VERSION ""

NS_ :

BS_:

BU_: TPMS
VAL_TABLE_ FMI 31 "Not available" 19 "Received network data in error" 18 "Below normal (moderately severe)" 17 "Below normal (least severe)" 16 "Above normal (moderately severe)" 15 "Above normal (least severe)" 14 "Special intstructions" 13 "Out of calibration" 12 "Bad intelligent device" 11 "Root cause not known" 10 "Abnormal rate of change" 9 "Abnormal update rate" 8 "Abnormal frequency" 7 "Mechanical system not responding" 6 "Current above normal" 5 "Current below normal" 4 "Voltage below normal" 3 "Voltage above normal" 2 "Data erratic" 1 "Below normal (most severe)" 0 "Above normal (most severe)" ;

BO_ 3221225472 VECTOR__INDEPENDENT_SIG_MSG: 0 Vector__XXX
 SG_ ParameterGroupNumber : 0|24@1- (1,0) [0|16777215] "" Vector__XXX
 SG_ TireTemp : 0|16@1+ (0.03125,-273) [-273|1734.96875] "deg C" Vector__XXX
 SG_ TirePressThresholdDetection : 0|3@1+ (1,0) [0|7] "" Vector__XXX
 SG_ TirePress : 0|8@1+ (4,0) [0|1000] "kPa" Vector__XXX
 SG_ TrailerWeight : 0|16@1+ (2,0) [0|128510] "kg" Vector__XXX
 SG_ TireAirLeakageRate : 0|16@1+ (0.1,0) [0|6425.5] "Pa/s" Vector__XXX
 SG_ ReferenceTirePressSetting : 0|8@1+ (1,0) [0|2000] "kPa" Vector__XXX
 SG_ ReferenceTirePress : 0|8@1+ (1,0) [0|2000] "kPa" Vector__XXX
 SG_ CTIWheelEndElectricalFault : 0|2@1+ (1,0) [0|3] "" Vector__XXX
 SG_ CTITireStatus : 0|2@1+ (1,0) [0|3] "" Vector__XXX
 SG_ CTIWheelSensorStatus : 0|2@1+ (1,0) [0|3] "" Vector__XXX
 SG_ EngTurningGearEngaged : 0|2@1+ (1,0) [0|3] "" Vector__XXX

BO_ 2684354558 CAPL_MSG: 1785 Vector__XXX

BO_ 2566838526 CA: 9 Vector__XXX
 SG_ AddressAssignment : 64|8@1+ (1,0) [0|255] "" Vector__XXX
 SG_ ArbitraryAddressCapable : 63|1@1+ (1,0) [0|1] "" Vector__XXX
 SG_ IndustryGroup M : 60|3@1+ (1,0) [0|7] "" Vector__XXX
 SG_ VehicleSystemInstance : 56|4@1+ (1,0) [0|15] "" Vector__XXX
 SG_ Function : 40|8@1+ (1,0) [0|255] "" Vector__XXX
 SG_ VehicleSystem m0 : 49|7@1+ (1,0) [0|127] "" Vector__XXX
 SG_ FunctionInstance : 35|5@1+ (1,0) [0|31] "" Vector__XXX
 SG_ ECUInstance : 32|3@1+ (1,0) [0|7] "" Vector__XXX
 SG_ ManufacturerCode : 21|11@1+ (1,0) [0|2047] "" Vector__XXX
 SG_ IdentityNumber : 0|21@1+ (1,0) [0|2097152] "" Vector__XXX
 SG_ VehicleSystem5 m5 : 49|7@1+ (1,0) [0|127] "" Vector__XXX
 SG_ VehicleSystem4 m4 : 49|7@1+ (1,0) [0|127] "" Vector__XXX
 SG_ VehicleSystem3 m3 : 49|7@1+ (1,0) [0|127] "" Vector__XXX
 SG_ VehicleSystem2 m2 : 49|7@1+ (1,0) [0|127] "" Vector__XXX
 SG_ VehicleSystem1 m1 : 49|7@1+ (1,0) [0|127] "" Vector__XXX

BO_ 2565537534 RQST: 8 Vector__XXX
 SG_ ParameterGroupNumber : 0|24@1+ (1,0) [0|16777215] "" Vector__XXX

BO_ 2632711934 TPDT: 8 Vector__XXX
 SG_ SequenceNumber : 0|8@1+ (1,0) [0|255] "" Vector__XXX

BO_ 2632777470 TPCM: 8 Vector__XXX
 SG_ TotalNumberOfPacketsEoMA m19 : 24|8@1+ (1,0) [0|255] "" Vector__XXX
 SG_ TotalMessageSizeEoMA m19 : 8|16@1+ (1,0) [0|64255] "counts" Vector__XXX
 SG_ TotalMessageSizeBAM m32 : 8|16@1+ (1,0) [0|64255] "counts" Vector__XXX
 SG_ TotalNumberOfPacketsBAM m32 : 24|8@1+ (1,0) [0|255] "" Vector__XXX
 SG_ ConnectionAbortReason m255 : 8|8@1+ (1,0) [0|255] "" Vector__XXX
 SG_ NextPacketNumberToBeSent m17 : 16|8@1+ (1,0) [0|255] "" Vector__XXX
 SG_ NumberOfPacketsThatCanBeSent m17 : 8|8@1+ (1,0) [0|255] "" Vector__XXX
 SG_ PGNumber : 40|24@1+ (1,0) [0|16777200] "" Vector__XXX
 SG_ MaximumNumberOfPackets m16 : 32|8@1+ (1,0) [0|255] "" Vector__XXX
 SG_ TotalNumberOfPackets m16 : 24|8@1+ (1,0) [0|255] "" Vector__XXX
 SG_ TotalMessageSize m16 : 8|16@1+ (1,0) [0|64255] "counts" Vector__XXX
 SG_ ControlByte M : 0|8@1+ (1,0) [0|255] "" Vector__XXX

BO_ 2561605374 TPRS: 8 Vector__XXX
 SG_ TireLocation M : 0|8@1+ (1,0) [0|255] "" Vector__XXX
 SG_ ReferenceTirePressSetting_00 m0 : 8|8@1+ (8,0) [0|2000] "kPa" Vector__XXX
 SG_ ReferenceTirePressSetting_01 m1 : 8|8@1+ (8,0) [0|2000] "kPa" Vector__XXX
 SG_ ReferenceTirePressSetting_10 m16 : 8|8@1+ (8,0) [0|2000] "kPa" Vector__XXX
 SG_ ReferenceTirePressSetting_11 m17 : 8|8@1+ (8,0) [0|2000] "kPa" Vector__XXX
 SG_ ReferenceTirePressSetting_12 m18 : 8|8@1+ (8,0) [0|2000] "kPa" Vector__XXX
 SG_ ReferenceTirePressSetting_13 m19 : 8|8@1+ (8,0) [0|2000] "kPa" Vector__XXX
 SG_ ReferenceTirePressSetting_20 m32 : 8|8@1+ (8,0) [0|2000] "kPa" Vector__XXX
 SG_ ReferenceTirePressSetting_21 m33 : 8|8@1+ (8,0) [0|2000] "kPa" Vector__XXX
 SG_ ReferenceTirePressSetting_22 m34 : 8|8@1+ (8,0) [0|2000] "kPa" Vector__XXX
 SG_ ReferenceTirePressSetting_23 m35 : 8|8@1+ (8,0) [0|2000] "kPa" Vector__XXX
 SG_ ReferenceTirePressSetting_30 m48 : 8|8@1+ (8,0) [0|2000] "kPa" Vector__XXX
 SG_ ReferenceTirePressSetting_31 m49 : 8|8@1+ (8,0) [0|2000] "kPa" Vector__XXX
 SG_ ReferenceTirePressSetting_32 m50 : 8|8@1+ (8,0) [0|2000] "kPa" Vector__XXX
 SG_ ReferenceTirePressSetting_33 m51 : 8|8@1+ (8,0) [0|2000] "kPa" Vector__XXX

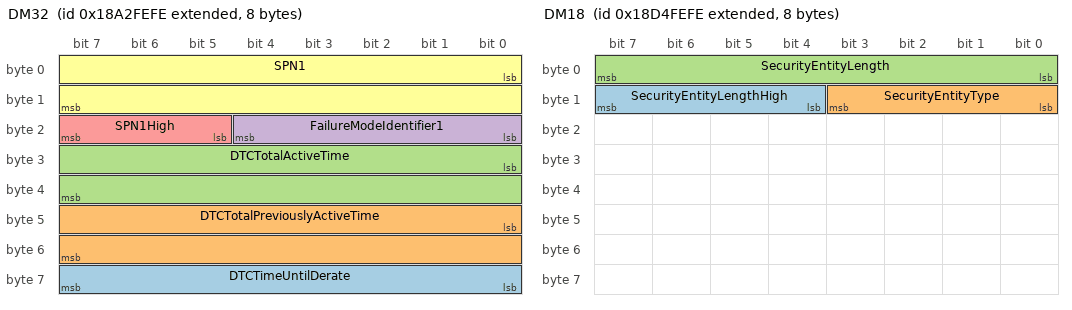
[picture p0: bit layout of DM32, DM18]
BO_ 2560818942 DM32: 8 Vector__XXX
 SG_ DTCTimeUntilDerate : 56|8@1+ (0.25,0) [0|62.5] "hr" Vector__XXX
 SG_ DTCTotalPreviouslyActiveTime : 40|16@1+ (0.2,0) [0|12851] "hr" Vector__XXX
 SG_ DTCTotalActiveTime : 24|16@1+ (0.2,0) [0|12851] "hr" Vector__XXX
 SG_ FailureModeIdentifier1 : 16|5@1+ (1,0) [0|0] "" Vector__XXX
 SG_ SPN1High : 21|3@1+ (1,0) [0|7] "" Vector__XXX
 SG_ SPN1 : 0|16@1+ (1,0) [0|65536] "" Vector__XXX

BO_ 2566764798 DM26: 8 Vector__XXX
 SG_ NMHCConvertingCatalystCompleted : 60|1@1+ (1,0) [0|1] "" Vector__XXX
 SG_ NMHCConvertingCatalystEnabled : 44|1@1+ (1,0) [0|1] "" Vector__XXX
 SG_ NOxConvertingCatalystAdsorberCom : 59|1@1+ (1,0) [0|1] "" Vector__XXX
 SG_ NOxConvertingCatalystAdsorberEna : 43|1@1+ (1,0) [0|1] "" Vector__XXX
 SG_ DieselParticulateFilterCompleted : 58|1@1+ (1,0) [0|1] "" Vector__XXX
 SG_ DieselParticulateFilterEnabled : 42|1@1+ (1,0) [0|1] "" Vector__XXX
 SG_ BoostPressureControlSystemComple : 57|1@1+ (1,0) [0|1] "" Vector__XXX
 SG_ BoostPressureControlSystemEnable : 41|1@1- (1,0) [0|0] "" Vector__XXX
 SG_ MisfireMonitoringComplete : 28|1@1+ (1,0) [0|1] "" Vector__XXX
 SG_ MisfireMonitoringEnabled : 24|1@1+ (1,0) [0|0] "" Vector__XXX
 SG_ FuelSystemMonitoringEnabled : 25|1@1+ (1,0) [0|1] "" Vector__XXX
 SG_ ComprehensiveComptMonComplete : 30|1@1+ (1,0) [0|1] "" Vector__XXX
 SG_ ComprehensiveCompMonEnabled : 26|1@1+ (1,0) [0|1] "" Vector__XXX
 SG_ SecondAirSystemMonComplete : 51|1@1+ (1,0) [0|1] "" Vector__XXX
 SG_ SecondAirSystemMonEnabled : 35|1@1+ (1,0) [0|1] "" Vector__XXX
 SG_ OxygenSensorMonComplete : 53|1@1+ (1,0) [0|1] "" Vector__XXX
 SG_ OxygenSensorMonEnabled : 37|1@1+ (1,0) [0|1] "" Vector__XXX
 SG_ OxygenSensorHeaterMonComplete : 54|1@1+ (1,0) [0|1] "" Vector__XXX
 SG_ OxygenSensorHeaterMonEnabled : 38|1@1+ (1,0) [0|1] "" Vector__XXX
 SG_ HeatedCatalystMonComplete : 49|1@1+ (1,0) [0|1] "" Vector__XXX
 SG_ HeatedCatalystMonEnabled : 33|1@1+ (1,0) [0|1] "" Vector__XXX
 SG_ EvaporativeSystemMonComplete : 50|1@1+ (1,0) [0|1] "" Vector__XXX
 SG_ EvaporativeSystemMonEnabled : 34|1@1+ (1,0) [0|1] "" Vector__XXX
 SG_ EGRSystemMonitoringComplete : 55|1@1+ (1,0) [0|1] "" Vector__XXX
 SG_ EGRSystemMonitoringEnabled : 39|1@1+ (1,0) [0|1] "" Vector__XXX
 SG_ ColdStartAidSystemMonComplete : 56|1@1+ (1,0) [0|1] "" Vector__XXX
 SG_ ColdStartAidSystemMonEnabled : 40|1@1+ (1,0) [0|1] "" Vector__XXX
 SG_ CatalystMonComplete : 48|1@1+ (1,0) [0|1] "" Vector__XXX
 SG_ CatalystMonEnabled : 32|1@1+ (1,0) [0|1] "" Vector__XXX
 SG_ ACSystemRefrigerantMonComplete : 52|1@1+ (1,0) [0|1] "" Vector__XXX
 SG_ ACSystemRefrigerantMonEnabled : 36|1@1+ (1,0) [0|1] "" Vector__XXX
 SG_ FuelSystemMonitoringComplete : 29|1@1+ (1,0) [0|1] "" Vector__XXX
 SG_ NumOfWarmUpsSinceDTCsCleared : 16|8@1+ (1,0) [0|250] "" Vector__XXX
 SG_ TimeSinceEngineStart : 0|16@1+ (1,0) [0|64255] "sec" Vector__XXX

BO_ 2564095742 DM18: 8 Vector__XXX
 SG_ SecurityEntityLengthHigh : 12|4@1+ (1,0) [0|255] "Byte" Vector__XXX
 SG_ SecurityEntityType : 8|4@1+ (1,0) [0|15] "" Vector__XXX
 SG_ SecurityEntityLength : 0|8@1+ (1,0) [0|1785] "Byte" Vector__XXX

BO_ 2566765054 TPRI: 8 Vector__XXX
 SG_ ReferenceTirePress_33 m51 : 8|8@1+ (8,0) [0|2000] "kPa" Vector__XXX
 SG_ ReferenceTirePress_32 m50 : 8|8@1+ (8,0) [0|2000] "kPa" Vector__XXX
 SG_ ReferenceTirePress_31 m49 : 8|8@1+ (8,0) [0|2000] "kPa" Vector__XXX
 SG_ ReferenceTirePress_30 m48 : 8|8@1+ (8,0) [0|2000] "kPa" Vector__XXX
 SG_ ReferenceTirePress_23 m35 : 8|8@1+ (8,0) [0|2000] "kPa" Vector__XXX
 SG_ ReferenceTirePress_22 m34 : 8|8@1+ (8,0) [0|2000] "kPa" Vector__XXX
 SG_ ReferenceTirePress_21 m33 : 8|8@1+ (8,0) [0|2000] "kPa" Vector__XXX
 SG_ ReferenceTirePress_20 m32 : 8|8@1+ (8,0) [0|2000] "kPa" Vector__XXX
 SG_ ReferenceTirePress_13 m19 : 8|8@1+ (8,0) [0|2000] "kPa" Vector__XXX
 SG_ ReferenceTirePress_12 m18 : 8|8@1+ (8,0) [0|2000] "kPa" Vector__XXX
 SG_ ReferenceTirePress_11 m17 : 8|8@1+ (8,0) [0|2000] "kPa" Vector__XXX
 SG_ ReferenceTirePress_10 m16 : 8|8@1+ (8,0) [0|2000] "kPa" Vector__XXX
 SG_ ReferenceTirePress_01 m1 : 8|8@1+ (8,0) [0|2000] "kPa" Vector__XXX
 SG_ ReferenceTirePress_00 m0 : 8|8@1+ (8,0) [0|2000] "kPa" Vector__XXX
 SG_ TireLocation M : 0|8@1+ (1,0) [0|255] "" Vector__XXX

BO_ 2566845694 TIRE: 8 Vector__XXX
 SG_ TirePressThresholdDetection_13 m19 : 61|3@1+ (1,0) [0|7] "" Vector__XXX
 SG_ TirePressThresholdDetection_12 m18 : 61|3@1+ (1,0) [0|7] "" Vector__XXX
 SG_ TirePressThresholdDetection_11 m17 : 61|3@1+ (1,0) [0|7] "" Vector__XXX
 SG_ TirePressThresholdDetection_10 m16 : 61|3@1+ (1,0) [0|7] "" Vector__XXX
 SG_ TirePressThresholdDetection_01 m1 : 61|3@1+ (1,0) [0|7] "" Vector__XXX
 SG_ TirePress_33 m51 : 8|8@1+ (4,0) [0|1000] "kPa" Vector__XXX
 SG_ TirePress_32 m50 : 8|8@1+ (4,0) [0|1000] "kPa" Vector__XXX
 SG_ TirePress_31 m49 : 8|8@1+ (4,0) [0|1000] "kPa" Vector__XXX
 SG_ TirePress_30 m48 : 8|8@1+ (4,0) [0|1000] "kPa" Vector__XXX
 SG_ TirePress_23 m35 : 8|8@1+ (4,0) [0|1000] "kPa" Vector__XXX
 SG_ TirePress_22 m34 : 8|8@1+ (4,0) [0|1000] "kPa" Vector__XXX
 SG_ TirePress_21 m33 : 8|8@1+ (4,0) [0|1000] "kPa" Vector__XXX
 SG_ TirePress_20 m32 : 8|8@1+ (4,0) [0|1000] "kPa" Vector__XXX
 SG_ TirePress_13 m19 : 8|8@1+ (4,0) [0|1000] "kPa" Vector__XXX
 SG_ TirePress_12 m18 : 8|8@1+ (4,0) [0|1000] "kPa" Vector__XXX
 SG_ TirePress_11 m17 : 8|8@1+ (4,0) [0|1000] "kPa" Vector__XXX
 SG_ TirePress_10 m16 : 8|8@1+ (4,0) [0|1000] "kPa" Vector__XXX
 SG_ TireAirLeakageRate_33 m51 : 40|16@1+ (0.1,0) [0|6425.5] "Pa/s" Vector__XXX
 SG_ TireAirLeakageRate_32 m50 : 40|16@1+ (0.1,0) [0|6425.5] "Pa/s" Vector__XXX
 SG_ TireAirLeakageRate_31 m49 : 40|16@1+ (0.1,0) [0|6425.5] "Pa/s" Vector__XXX
 SG_ TireAirLeakageRate_30 m48 : 40|16@1+ (0.1,0) [0|6425.5] "Pa/s" Vector__XXX
 SG_ TireAirLeakageRate_23 m35 : 40|16@1+ (0.1,0) [0|6425.5] "Pa/s" Vector__XXX
 SG_ TireAirLeakageRate_22 m34 : 40|16@1+ (0.1,0) [0|6425.5] "Pa/s" Vector__XXX
 SG_ TireAirLeakageRate_21 m33 : 40|16@1+ (0.1,0) [0|6425.5] "Pa/s" Vector__XXX
 SG_ TireAirLeakageRate_20 m32 : 40|16@1+ (0.1,0) [0|6425.5] "Pa/s" Vector__XXX
 SG_ TireAirLeakageRate_13 m19 : 40|16@1+ (0.1,0) [0|6425.5] "Pa/s" Vector__XXX
 SG_ TireAirLeakageRate_12 m18 : 40|16@1+ (0.1,0) [0|6425.5] "Pa/s" Vector__XXX
 SG_ TireAirLeakageRate_11 m17 : 40|16@1+ (0.1,0) [0|6425.5] "Pa/s" Vector__XXX
 SG_ TireAirLeakageRate_10 m16 : 40|16@1+ (0.1,0) [0|6425.5] "Pa/s" Vector__XXX
 SG_ TireAirLeakageRate_01 m1 : 40|16@1+ (0.1,0) [0|6425.5] "Pa/s" Vector__XXX
 SG_ TireAirLeakageRate_00 m0 : 40|16@1+ (0.1,0) [0|6425.5] "Pa/s" Vector__XXX
 SG_ CTIWheelSensorStatus_33 m51 : 32|2@1+ (1,0) [0|3] "" Vector__XXX
 SG_ CTIWheelSensorStatus_32 m50 : 32|2@1+ (1,0) [0|3] "" Vector__XXX
 SG_ CTIWheelSensorStatus_31 m49 : 32|2@1+ (1,0) [0|3] "" Vector__XXX
 SG_ CTIWheelSensorStatus_30 m48 : 32|2@1+ (1,0) [0|3] "" Vector__XXX
 SG_ CTIWheelSensorStatus_23 m35 : 32|2@1+ (1,0) [0|3] "" Vector__XXX
 SG_ CTIWheelSensorStatus_22 m34 : 32|2@1+ (1,0) [0|3] "" Vector__XXX
 SG_ CTIWheelSensorStatus_21 m33 : 32|2@1+ (1,0) [0|3] "" Vector__XXX
 SG_ CTIWheelSensorStatus_20 m32 : 32|2@1+ (1,0) [0|3] "" Vector__XXX
 SG_ CTIWheelSensorStatus_13 m19 : 32|2@1+ (1,0) [0|3] "" Vector__XXX
 SG_ CTIWheelSensorStatus_12 m18 : 32|2@1+ (1,0) [0|3] "" Vector__XXX
 SG_ CTIWheelSensorStatus_11 m17 : 32|2@1+ (1,0) [0|3] "" Vector__XXX
 SG_ CTIWheelSensorStatus_10 m16 : 32|2@1+ (1,0) [0|3] "" Vector__XXX
 SG_ CTIWheelSensorStatus_01 m1 : 32|2@1+ (1,0) [0|3] "" Vector__XXX
 SG_ CTIWheelEndElectricalFault_33 m51 : 36|2@1+ (1,0) [0|3] "" Vector__XXX
 SG_ CTIWheelEndElectricalFault_32 m50 : 36|2@1+ (1,0) [0|3] "" Vector__XXX
 SG_ CTIWheelEndElectricalFault_31 m49 : 36|2@1+ (1,0) [0|3] "" Vector__XXX
 SG_ CTIWheelEndElectricalFault_30 m48 : 36|2@1+ (1,0) [0|3] "" Vector__XXX
 SG_ CTIWheelEndElectricalFault_23 m35 : 36|2@1+ (1,0) [0|3] "" Vector__XXX
 SG_ CTIWheelEndElectricalFault_22 m34 : 36|2@1+ (1,0) [0|3] "" Vector__XXX
 SG_ CTIWheelEndElectricalFault_21 m33 : 36|2@1+ (1,0) [0|3] "" Vector__XXX
 SG_ CTIWheelEndElectricalFault_20 m32 : 36|2@1+ (1,0) [0|3] "" Vector__XXX
 SG_ CTIWheelEndElectricalFault_13 m19 : 36|2@1+ (1,0) [0|3] "" Vector__XXX
 SG_ CTIWheelEndElectricalFault_12 m18 : 36|2@1+ (1,0) [0|3] "" Vector__XXX
 SG_ CTIWheelEndElectricalFault_11 m17 : 36|2@1+ (1,0) [0|3] "" Vector__XXX
 SG_ CTIWheelEndElectricalFault_10 m16 : 36|2@1+ (1,0) [0|3] "" Vector__XXX
 SG_ CTIWheelEndElectricalFault_01 m1 : 36|2@1+ (1,0) [0|3] "" Vector__XXX
 SG_ CTITireStatus_33 m51 : 34|2@1+ (1,0) [0|3] "" Vector__XXX
 SG_ CTITireStatus_32 m50 : 34|2@1+ (1,0) [0|3] "" Vector__XXX
 SG_ CTITireStatus_31 m49 : 34|2@1+ (1,0) [0|3] "" Vector__XXX
 SG_ CTITireStatus_30 m48 : 34|2@1+ (1,0) [0|3] "" Vector__XXX
 SG_ CTITireStatus_23 m35 : 34|2@1+ (1,0) [0|3] "" Vector__XXX
 SG_ CTITireStatus_22 m34 : 34|2@1+ (1,0) [0|3] "" Vector__XXX
 SG_ CTITireStatus_21 m33 : 34|2@1+ (1,0) [0|3] "" Vector__XXX
 SG_ CTITireStatus_20 m32 : 34|2@1+ (1,0) [0|3] "" Vector__XXX
 SG_ CTITireStatus_13 m19 : 34|2@1+ (1,0) [0|3] "" Vector__XXX
 SG_ CTITireStatus_12 m18 : 34|2@1+ (1,0) [0|3] "" Vector__XXX
 SG_ CTITireStatus_11 m17 : 34|2@1+ (1,0) [0|3] "" Vector__XXX
 SG_ CTITireStatus_10 m16 : 34|2@1+ (1,0) [0|3] "" Vector__XXX
 SG_ CTITireStatus_01 m1 : 34|2@1+ (1,0) [0|3] "" Vector__XXX
 SG_ TireTemp_11 m17 : 16|16@1+ (0.03125,-273) [-273|1735] "°C" Vector__XXX
 SG_ TireTemp_33 m51 : 16|16@1+ (0.03125,-273) [-273|1735] "°C" Vector__XXX
 SG_ TireTemp_32 m50 : 16|16@1+ (0.03125,-273) [-273|1735] "°C" Vector__XXX
 SG_ TireTemp_31 m49 : 16|16@1+ (0.03125,-273) [-273|1735] "°C" Vector__XXX
 SG_ TireTemp_30 m48 : 16|16@1+ (0.03125,-273) [-273|1735] "°C" Vector__XXX
 SG_ TireTemp_23 m35 : 16|16@1+ (0.03125,-273) [-273|1735] "°C" Vector__XXX
 SG_ TireTemp_22 m34 : 16|16@1+ (0.03125,-273) [-273|1735] "°C" Vector__XXX
 SG_ TireTemp_21 m33 : 16|16@1+ (0.03125,-273) [-273|1735] "°C" Vector__XXX
 SG_ TireTemp_20 m32 : 16|16@1+ (0.03125,-273) [-273|1735] "°C" Vector__XXX
 SG_ TireTemp_13 m19 : 16|16@1+ (0.03125,-273) [-273|1735] "°C" Vector__XXX
 SG_ TireTemp_12 m18 : 16|16@1+ (0.03125,-273) [-273|1735] "°C" Vector__XXX
 SG_ TireTemp_10 m16 : 16|16@1+ (0.03125,-273) [-273|1735] "°C" Vector__XXX
 SG_ TireTemp_01 m1 : 16|16@1+ (0.03125,-273) [-273|1735] "°C" Vector__XXX
 SG_ TireTemp_00 m0 : 16|16@1+ (0.03125,-273) [-273|1735] "°C" Vector__XXX
 SG_ TirePressThresholdDetection_33 m51 : 61|3@1+ (1,0) [0|7] "" Vector__XXX
 SG_ TirePressThresholdDetection_32 m50 : 61|3@1+ (1,0) [0|7] "" Vector__XXX
 SG_ TirePressThresholdDetection_31 m49 : 61|3@1+ (1,0) [0|7] "" Vector__XXX
 SG_ TirePressThresholdDetection_30 m48 : 61|3@1+ (1,0) [0|7] "" Vector__XXX
 SG_ TirePressThresholdDetection_23 m35 : 61|3@1+ (1,0) [0|7] "" Vector__XXX
 SG_ TirePressThresholdDetection_22 m34 : 61|3@1+ (1,0) [0|7] "" Vector__XXX
 SG_ TirePressThresholdDetection_21 m33 : 61|3@1+ (1,0) [0|7] "" Vector__XXX
 SG_ TirePressThresholdDetection_20 m32 : 61|3@1+ (1,0) [0|7] "" Vector__XXX
 SG_ TirePressThresholdDetection_00 m0 : 61|3@1+ (1,0) [0|7] "" Vector__XXX
 SG_ TirePress_01 m1 : 8|8@1+ (4,0) [0|1000] "kPa" Vector__XXX
 SG_ TirePress_00 m0 : 8|8@1+ (4,0) [0|1000] "kPa" Vector__XXX
 SG_ CTIWheelSensorStatus_00 m0 : 32|2@1+ (1,0) [0|3] "" Vector__XXX
 SG_ CTIWheelEndElectricalFault_00 m0 : 36|2@1+ (1,0) [0|3] "" Vector__XXX
 SG_ CTITireStatus_00 m0 : 34|2@1+ (1,0) [0|3] "" Vector__XXX
 SG_ TireLocation M : 0|8@1+ (1,0) [0|255] "" Vector__XXX

BO_ 2566839038 SOFT: 8 Vector__XXX
 SG_ NmbrOfSftwreIdentificationFields : 0|8@1+ (1,0) [0|250] "steps" Vector__XXX
 SG_ SoftwareIdentification : 8|8@1+ (1.02,0) [0|255] "per byte" Vector__XXX

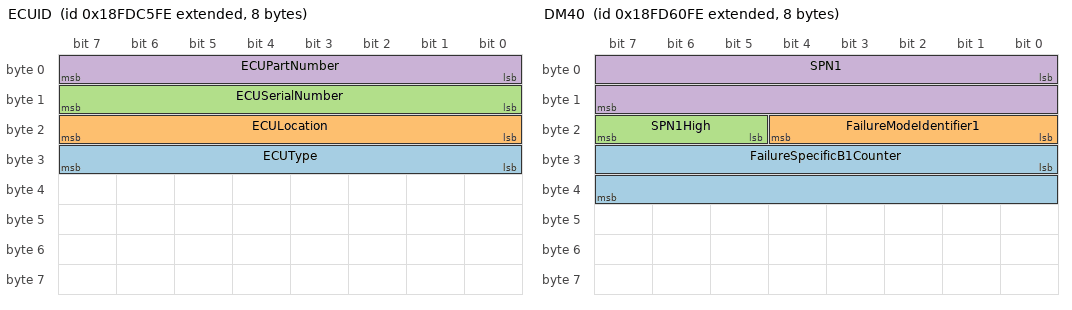
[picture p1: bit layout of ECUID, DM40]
BO_ 2566768126 ECUID: 8 Vector__XXX
 SG_ ECUType : 24|8@1+ (1.02,0) [0|255] "per byte" Vector__XXX
 SG_ ECULocation : 16|8@1+ (1.02,0) [0|255] "per byte" Vector__XXX
 SG_ ECUSerialNumber : 8|8@1+ (1.02,0) [0|255] "per byte" Vector__XXX
 SG_ ECUPartNumber : 0|8@1+ (1.02,0) [0|255] "per byte" Vector__XXX

BO_ 2566742270 DM40: 8 Vector__XXX
 SG_ FailureSpecificB1Counter : 24|16@1+ (0.1,0) [0|6425.5] "hr" Vector__XXX
 SG_ FailureModeIdentifier1 : 16|5@1+ (1,0) [0|0] "" Vector__XXX
 SG_ SPN1High : 21|3@1+ (1,0) [0|7] "" Vector__XXX
 SG_ SPN1 : 0|16@1+ (1,0) [0|65536] "" Vector__XXX

BO_ 2566742526 DM39: 8 Vector__XXX
 SG_ SysGreatestB1Counter : 32|16@1+ (0.1,0) [0|6425.5] "hr" Vector__XXX
 SG_ SysCumulativeContinuousMITime : 0|32@1+ (0.05,0) [0|210554060.75] "hr" Vector__XXX

BO_ 2566742782 DM38: 8 Vector__XXX
 SG_ RegulationDescription : 0|8@1+ (1,0) [0|255] "" Vector__XXX

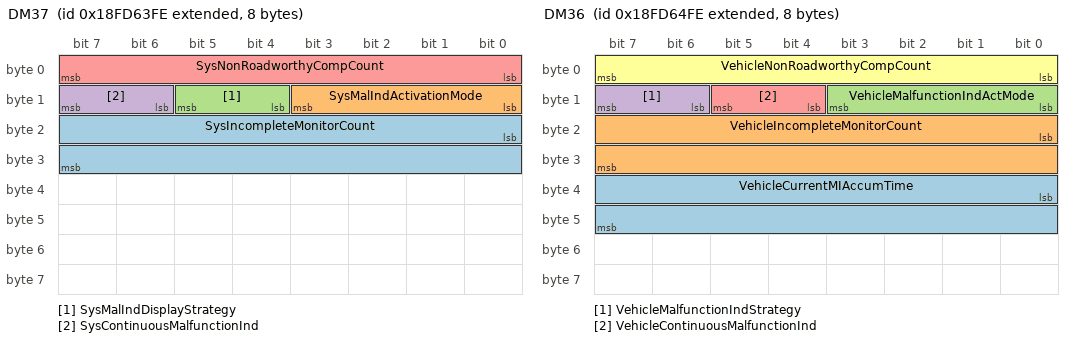
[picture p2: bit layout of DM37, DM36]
BO_ 2566743038 DM37: 8 Vector__XXX
 SG_ SysIncompleteMonitorCount : 16|16@1+ (1,0) [0|64512] "" Vector__XXX
 SG_ SysMalIndActivationMode : 8|4@1+ (1,0) [0|15] "" Vector__XXX
 SG_ SysMalIndDisplayStrategy : 12|2@1+ (1,0) [0|3] "" Vector__XXX
 SG_ SysContinuousMalfunctionInd : 14|2@1+ (1,0) [0|3] "" Vector__XXX
 SG_ SysNonRoadworthyCompCount : 0|8@1+ (1,0) [0|250] "" Vector__XXX

BO_ 2566743294 DM36: 8 Vector__XXX
 SG_ VehicleCurrentMIAccumTime : 32|16@1+ (1,0) [0|64255] "min" Vector__XXX
 SG_ VehicleIncompleteMonitorCount : 16|16@1+ (1,0) [0|64255] "" Vector__XXX
 SG_ VehicleMalfunctionIndActMode : 8|4@1+ (1,0) [0|15] "" Vector__XXX
 SG_ VehicleMalfunctionIndStrategy : 14|2@1+ (1,0) [0|3] "" Vector__XXX
 SG_ VehicleContinuousMalfunctionInd : 12|2@1+ (1,0) [0|3] "" Vector__XXX
 SG_ VehicleNonRoadworthyCompCount : 0|8@1+ (1,0) [0|250] "" Vector__XXX

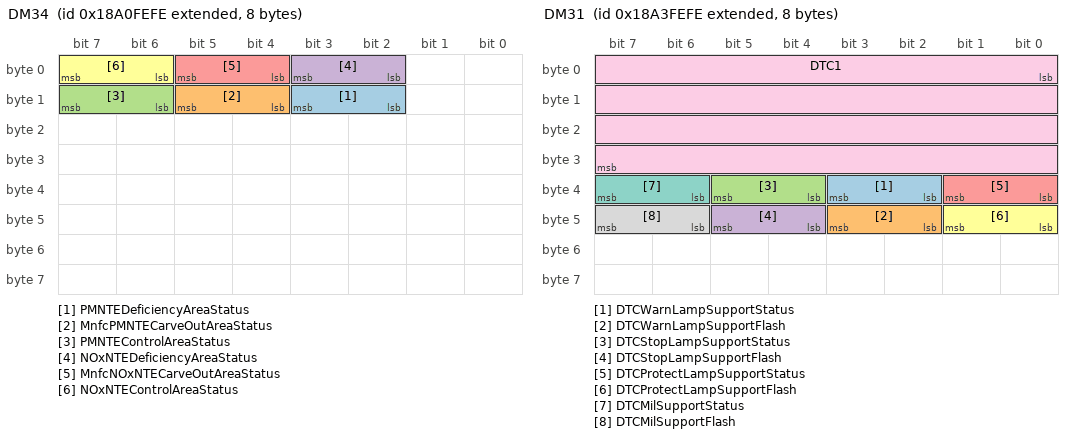
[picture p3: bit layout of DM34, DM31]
BO_ 2560687870 DM34: 8 Vector__XXX
 SG_ PMNTEDeficiencyAreaStatus : 10|2@1+ (1,0) [0|3] "" Vector__XXX
 SG_ MnfcPMNTECarveOutAreaStatus : 12|2@1+ (1,0) [0|3] "" Vector__XXX
 SG_ PMNTEControlAreaStatus : 14|2@1+ (1,0) [0|3] "" Vector__XXX
 SG_ NOxNTEDeficiencyAreaStatus : 2|2@1+ (1,0) [0|3] "" Vector__XXX
 SG_ MnfcNOxNTECarveOutAreaStatus : 4|2@1+ (1,0) [0|3] "" Vector__XXX
 SG_ NOxNTEControlAreaStatus : 6|2@1+ (1,0) [0|3] "" Vector__XXX

BO_ 2292317950 DM33: 9 Vector__XXX
 SG_ AECDEngineHours1Timer2 : 40|32@1+ (1,0) [0|4294967295] "min" Vector__XXX
 SG_ AECDEngineHours1Timer1 : 8|32@1+ (1,0) [0|4294967295] "min" Vector__XXX
 SG_ AECDNumber1 : 0|8@1+ (1,0) [0|250] "" Vector__XXX

BO_ 2560884478 DM31: 8 Vector__XXX
 SG_ DTCWarnLampSupportStatus : 34|2@1+ (1,0) [0|3] "" Vector__XXX
 SG_ DTCWarnLampSupportFlash : 42|2@1+ (1,0) [0|3] "" Vector__XXX
 SG_ DTCStopLampSupportStatus : 36|2@1+ (1,0) [0|3] "" Vector__XXX
 SG_ DTCStopLampSupportFlash : 44|2@1+ (1,0) [0|3] "" Vector__XXX
 SG_ DTCProtectLampSupportStatus : 32|2@1+ (1,0) [0|3] "" Vector__XXX
 SG_ DTCProtectLampSupportFlash : 40|2@1+ (1,0) [0|3] "" Vector__XXX
 SG_ DTCMilSupportStatus : 38|2@1+ (1,0) [0|3] "" Vector__XXX
 SG_ DTCMilSupportFlash : 46|2@1+ (1,0) [0|3] "" Vector__XXX
 SG_ DTC1 : 0|32@1+ (1,0) [0|4294967295] "" Vector__XXX

BO_ 2560950014 DM30: 12 Vector__XXX
 SG_ TestLimitMinimum : 80|16@1+ (1,0) [0|64255] "" Vector__XXX
 SG_ TestLimitMaximum : 64|16@1+ (1,0) [0|64255] "" Vector__XXX
 SG_ TestValue : 48|16@1+ (1,0) [0|64255] "" Vector__XXX
 SG_ SlotId : 32|16@1+ (1,0) [0|64255] "" Vector__XXX
 SG_ TestIdentifier : 0|8@1+ (1,0) [0|255] "" Vector__XXX
 SG_ FailureModeIdentifier1 : 24|5@1+ (1,0) [0|0] "" Vector__XXX
 SG_ SPN1High : 29|3@1+ (1,0) [0|7] "" Vector__XXX
 SG_ SPN1 : 8|16@1+ (1,0) [0|65536] "" Vector__XXX

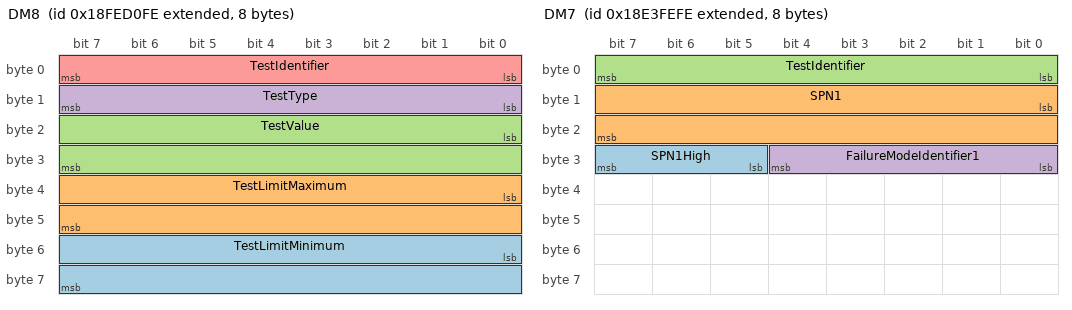
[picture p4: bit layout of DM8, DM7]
BO_ 2566836478 DM8: 8 Vector__XXX
 SG_ TestLimitMinimum : 48|16@1+ (1,0) [0|64255] "" Vector__XXX
 SG_ TestLimitMaximum : 32|16@1+ (1,0) [0|64255] "" Vector__XXX
 SG_ TestValue : 16|16@1+ (1,0) [0|64255] "" Vector__XXX
 SG_ TestType : 8|8@1+ (1,0) [1|64] "" Vector__XXX
 SG_ TestIdentifier : 0|8@1+ (1,0) [1|64] "" Vector__XXX

BO_ 2565078782 DM7: 8 Vector__XXX
 SG_ SPN1High : 29|3@1+ (1,0) [0|7] "" Vector__XXX
 SG_ SPN1 : 8|16@1+ (1,0) [0|65536] "" Vector__XXX
 SG_ TestIdentifier : 0|8@1+ (1,0) [1|64] "" Vector__XXX
 SG_ FailureModeIdentifier1 : 24|5@1+ (1,0) [0|0] "" Vector__XXX

BO_ 2566836222 DM6: 22 Vector__XXX
 SG_ FlashRedStopLamp : 12|2@1+ (1,0) [0|3] "" Vector__XXX
 SG_ FlashProtectLamp : 8|2@1+ (1,0) [0|3] "" Vector__XXX
 SG_ FlashMalfuncIndicatorLamp : 14|2@1+ (1,0) [0|3] "" Vector__XXX
 SG_ FlashAmberWarningLamp : 10|2@1+ (1,0) [0|3] "" Vector__XXX
 SG_ MalfunctionIndicatorLampStatus : 6|2@1+ (1,0) [0|3] "" Vector__XXX
 SG_ RedStopLampState : 4|2@1+ (1,0) [0|3] "" Vector__XXX
 SG_ AmberWarningLampStatus : 2|2@1+ (1,0) [0|3] "" Vector__XXX
 SG_ ProtectLampStatus : 0|2@1+ (1,0) [0|3] "" Vector__XXX
 SG_ DTC5 : 144|32@1+ (1,0) [0|4294967295] "" Vector__XXX
 SG_ DTC4 : 112|32@1+ (1,0) [0|4294967295] "" Vector__XXX
 SG_ DTC3 : 80|32@1+ (1,0) [0|4294967295] "" Vector__XXX
 SG_ DTC2 : 48|32@1+ (1,0) [0|4294967295] "" Vector__XXX
 SG_ DTC1 : 16|32@1+ (1,0) [0|4294967295] "" Vector__XXX

BO_ 2566835966 DM5: 8 Vector__XXX
 SG_ BoostPressureControlSystemStatus : 57|1@1- (1,0) [0|0] "" Vector__XXX
 SG_ DieselParticulateFilterStatus : 58|1@1- (1,0) [0|0] "" Vector__XXX
 SG_ NOxConvertingCatalystAdsorberSta : 59|1@1- (1,0) [0|0] "" Vector__XXX
 SG_ NMHCConvertingCatalystStatus : 60|1@1- (1,0) [0|0] "" Vector__XXX
 SG_ BoostPressureControlSystemSuppor : 41|1@1- (1,0) [0|0] "" Vector__XXX
 SG_ DieselParticulateFilterSupport : 42|1@1- (1,0) [0|0] "" Vector__XXX
 SG_ NOxConvertingCatalystAdsorberSup : 43|1@1- (1,0) [0|0] "" Vector__XXX
 SG_ NMHCConvertingCatalystSupport : 44|1@1- (1,0) [0|0] "" Vector__XXX
 SG_ MisfireMonitoringSupport : 24|1@1+ (1,0) [0|0] "" Vector__XXX
 SG_ OBDCompliance : 16|8@1+ (1,0) [0|240] "" Vector__XXX
 SG_ PreviouslyActiveTroubleCodes : 8|8@1+ (1,0) [0|240] "" Vector__XXX
 SG_ ActiveTroubleCodes : 0|8@1+ (1,0) [0|240] "" Vector__XXX
 SG_ SecondAirSystemMonStatus : 51|1@1+ (1,0) [0|1] "" Vector__XXX
 SG_ EvaporativeSystemMonStatus : 50|1@1+ (1,0) [0|1] "" Vector__XXX
 SG_ ACSystemRefrigerantMonStatus : 52|1@1+ (1,0) [0|1] "" Vector__XXX
 SG_ OxygenSensorHeaterMonStatus : 54|1@1+ (1,0) [0|1] "" Vector__XXX
 SG_ OxygenSensorMonStatus : 53|1@1+ (1,0) [0|1] "" Vector__XXX
 SG_ EGRSystemMonitoringStatus : 55|1@1+ (1,0) [0|1] "" Vector__XXX
 SG_ CatalystMonStatus : 48|1@1+ (1,0) [0|1] "" Vector__XXX
 SG_ ColdStartAidSystemMonStatus : 56|1@1+ (1,0) [0|1] "" Vector__XXX
 SG_ HeatedCatalystMonStatus : 49|1@1+ (1,0) [0|0] "" Vector__XXX
 SG_ CatalystMonSupp : 32|1@1+ (1,0) [0|1] "" Vector__XXX
 SG_ ColdStartAidSystemMonSupp : 40|1@1+ (1,0) [0|1] "" Vector__XXX
 SG_ HeatedCatalystMonSupp : 33|1@1+ (1,0) [0|0] "" Vector__XXX
 SG_ EvaporativeSystemMonSupp : 34|1@1+ (1,0) [0|1] "" Vector__XXX
 SG_ SecondAirSystemMonSupp : 35|1@1+ (1,0) [0|1] "" Vector__XXX
 SG_ ACSystemRefrigerantMonSupp : 36|1@1+ (1,0) [0|1] "" Vector__XXX
 SG_ OxygenSensorMonSupp : 37|1@1+ (1,0) [0|1] "" Vector__XXX
 SG_ OxygenSensorHeaterMonSupp : 38|1@1+ (1,0) [0|1] "" Vector__XXX
 SG_ EGRSystemMonitoringSupp : 39|1@1+ (1,0) [0|1] "" Vector__XXX
 SG_ MisfireMonitoringStatus : 28|1@1+ (1,0) [0|0] "" Vector__XXX
 SG_ ComprehensiveCompMonStatus : 30|1@1+ (1,0) [0|1] "" Vector__XXX
 SG_ FuelSystemMonitoringStatus : 29|1@1+ (1,0) [0|1] "" Vector__XXX
 SG_ ComprehensiveComponentMonSupp : 26|1@1+ (1,0) [0|0] "" Vector__XXX
 SG_ FuelSystemMonitoringSupport : 25|1@1+ (1,0) [0|1] "" Vector__XXX

BO_ 2566835710 DM4: 13 Vector__XXX
 SG_ EngIntakeManifold1Press : 48|8@1+ (2,0) [0|500] "kPa" Vector__XXX
 SG_ FreezeFrameLength : 0|8@1+ (1,0) [0|255] "Byte" Vector__XXX
 SG_ EngSpeed : 56|16@1+ (0.125,0) [0|8031.875] "rpm" Vector__XXX
 SG_ EngTorqueMode : 40|4@1+ (1,0) [0|15] "" Vector__XXX
 SG_ WheelBasedVehicleSpeed : 88|16@1+ (0.0039062485409696,0) [0|250.996] "km/h" Vector__XXX
 SG_ EngPercentLoadAtCurrentSpeed : 72|8@1+ (1,0) [0|250] "%" Vector__XXX
 SG_ EngCoolantTemp : 80|8@1+ (1,-40) [-40|210] "deg C" Vector__XXX
 SG_ DTC1 : 8|32@1+ (1,0) [0|4294967295] "" Vector__XXX

BO_ 2566835454 DM3: 0 Vector__XXX

BO_ 2566764542 DM25: 13 Vector__XXX
 SG_ ExpandedFreezeFrameLength : 0|8@1+ (1,0) [0|255] "Byte" Vector__XXX
 SG_ DTC1 : 8|32@1+ (1,0) [0|4294967295] "" Vector__XXX

BO_ 2566764286 DM24: 12 Vector__XXX
 SG_ SPNSupported1High : 21|3@1+ (1,0) [0|7] "" Vector__XXX
 SG_ SPNSupportTypeSTR3 : 82|1@1+ (1,0) [0|1] "" Vector__XXX
 SG_ SPNSupportTypeSTR2 : 50|1@1+ (1,0) [0|1] "" Vector__XXX
 SG_ SPNSupportTypeEFF3 : 80|1@1+ (1,0) [0|1] "" Vector__XXX
 SG_ SPNSupportTypeEFF2 : 48|1@1+ (1,0) [0|1] "" Vector__XXX
 SG_ SPNSupportTypeDS3 : 81|1@1+ (1,0) [0|1] "" Vector__XXX
 SG_ SPNSupportTypeDS2 : 49|1@1+ (1,0) [0|1] "" Vector__XXX
 SG_ SPNSupported3High : 85|3@1+ (1,0) [0|7] "" Vector__XXX
 SG_ SPNSupported2High : 53|3@1+ (1,0) [0|7] "" Vector__XXX
 SG_ SPNSupported3 : 64|16@1+ (1,0) [0|65535] "" Vector__XXX
 SG_ SPNSupported2 : 32|16@1+ (1,0) [0|65535] "" Vector__XXX
 SG_ SPNDataLength3 : 88|8@1+ (1,0) [0|240] "" Vector__XXX
 SG_ SPNSupportTypeSTR1 : 18|1@1+ (1,0) [0|1] "" Vector__XXX
 SG_ SPNSupportTypeDS1 : 17|1@1+ (1,0) [0|1] "" Vector__XXX
 SG_ SPNSupportTypeEFF1 : 16|1@1+ (1,0) [0|1] "" Vector__XXX
 SG_ SPNDataLength2 : 56|8@1+ (1,0) [0|240] "" Vector__XXX
 SG_ SPNDataLength1 : 24|8@1+ (1,0) [0|240] "" Vector__XXX
 SG_ SPNSupported1 : 0|16@1+ (1,0) [0|65535] "" Vector__XXX

BO_ 2566764030 DM23: 22 Vector__XXX
 SG_ FlashRedStopLamp : 12|2@1+ (1,0) [0|3] "" Vector__XXX
 SG_ FlashProtectLamp : 8|2@1+ (1,0) [0|3] "" Vector__XXX
 SG_ FlashMalfuncIndicatorLamp : 14|2@1+ (1,0) [0|3] "" Vector__XXX
 SG_ FlashAmberWarningLamp : 10|2@1+ (1,0) [0|3] "" Vector__XXX
 SG_ MalfunctionIndicatorLampStatus : 6|2@1+ (1,0) [0|3] "" Vector__XXX
 SG_ RedStopLampState : 4|2@1+ (1,0) [0|3] "" Vector__XXX
 SG_ AmberWarningLampStatus : 2|2@1+ (1,0) [0|3] "" Vector__XXX
 SG_ ProtectLampStatus : 0|2@1+ (1,0) [0|3] "" Vector__XXX
 SG_ DTC5 : 144|32@1+ (1,0) [0|4294967295] "" Vector__XXX
 SG_ DTC4 : 112|32@1+ (1,0) [0|4294967295] "" Vector__XXX
 SG_ DTC3 : 80|32@1+ (1,0) [0|4294967295] "" Vector__XXX
 SG_ DTC2 : 48|32@1+ (1,0) [0|4294967295] "" Vector__XXX
 SG_ DTC1 : 16|32@1+ (1,0) [0|4294967295] "" Vector__XXX

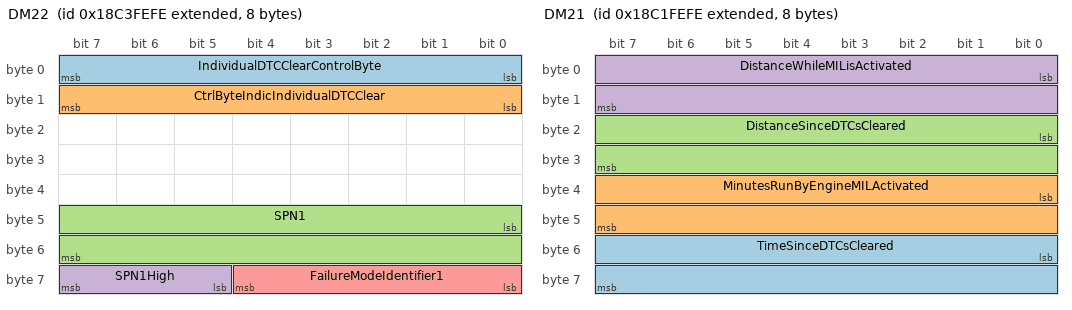
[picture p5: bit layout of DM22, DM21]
BO_ 2562981630 DM22: 8 Vector__XXX
 SG_ IndividualDTCClearControlByte : 0|8@1+ (1,0) [0|255] "" Vector__XXX
 SG_ CtrlByteIndicIndividualDTCClear : 8|8@1+ (1,0) [0|255] "" Vector__XXX
 SG_ SPN1 : 40|16@1+ (1,0) [0|65536] "" Vector__XXX
 SG_ SPN1High : 61|3@1+ (1,0) [0|7] "" Vector__XXX
 SG_ FailureModeIdentifier1 : 56|5@1+ (1,0) [0|0] "" Vector__XXX

BO_ 2562850558 DM21: 8 Vector__XXX
 SG_ TimeSinceDTCsCleared : 48|16@1+ (1,0) [0|64255] "mins" Vector__XXX
 SG_ MinutesRunByEngineMILActivated : 32|16@1+ (1,0) [0|64255] "mins" Vector__XXX
 SG_ DistanceSinceDTCsCleared : 16|16@1+ (1,0) [0|64255] "km" Vector__XXX
 SG_ DistanceWhileMILisActivated : 0|16@1+ (1,0) [0|64255] "km" Vector__XXX

BO_ 2562916094 DM20: 11 Vector__XXX
 SG_ ApplSysMonitorDenominator : 72|16@1+ (1,0) [0|65535] "" Vector__XXX
 SG_ ApplSysMonitorNumerator : 56|16@1+ (1,0) [0|65535] "" Vector__XXX
 SG_ SPNofApplSysMonitor : 32|24@1+ (1,0) [0|524287] "" Vector__XXX
 SG_ OBDMonitoringCondEncountered : 16|16@1+ (1,0) [0|65535] "" Vector__XXX
 SG_ IgnitionCycleCounter : 0|16@1+ (1,0) [0|65535] "" Vector__XXX

CM_ BO_ 3221225472 "This is a message for not used signals, created by Vector CANdb++ DBC OLE DB Provider.";
CM_ SG_ 3221225472 TireTemp "Temperature at the surface of the tire sidewall.";
CM_ SG_ 3221225472 TirePressThresholdDetection "Signal indicating the pressure level of the tire. The levels defined represent different pressure conditions of the tire:";
CM_ SG_ 3221225472 TirePress "Pressure at which air is contained in cavity formed by tire and rim.";
CM_ SG_ 3221225472 TrailerWeight "Total mass of freight-carrying vehicle designed to be pulled by truck, including the weight of the contents.";
CM_ SG_ 3221225472 TireAirLeakageRate "The pressure loss rate of a tire.";
CM_ SG_ 3221225472 ReferenceTirePressSetting "Reference value of the tire pressure setting as basis for the tire pressure monitoring";
CM_ SG_ 3221225472 ReferenceTirePress "Reference value of the tire pressure as basis for the tire pressure monitoring";
CM_ SG_ 3221225472 CTIWheelEndElectricalFault "Indicates the status of electrical fault on CTI wheel interface.";
CM_ SG_ 3221225472 CTITireStatus "Indicates the status of the tire.";
CM_ SG_ 3221225472 CTIWheelSensorStatus "Indicates whether the wheel is being monitored by the CTI controller.";
CM_ SG_ 3221225472 EngTurningGearEngaged "Status signal which indicates that the turning gear is engaged. The turning gear is used to turn the flywheel/crankshaft,";
CM_ SG_ 2565537534 ParameterGroupNumber "PGN which is requested by Request2 message";
CM_ BO_ 2632711934 "Transport Protocol - Data Transfer";
CM_ BO_ 2632777470 "Transport Protocol - Connection Management";
CM_ SG_ 2632777470 TotalNumberOfPacketsEoMA "Total number of packets for BAM message.Total number of packets received for RTS/CTS message.Total number of packets for RTS/CTS message.";
CM_ SG_ 2632777470 TotalMessageSizeEoMA "Total message size (in bytes) for BAM message.Total message size (in bytes) for RTS/CTS message.Total message size (in bytes) for RTS/CTS message.";
CM_ SG_ 2632777470 TotalMessageSizeBAM "Total message size (in bytes) for BAM message.Total message size (in bytes) for RTS/CTS message.Total message size (in bytes) for RTS/CTS message.";
CM_ SG_ 2632777470 TotalNumberOfPacketsBAM "Total number of packets for BAM message.Total number of packets received for RTS/CTS message.Total number of packets for RTS/CTS message.";
CM_ SG_ 2632777470 ConnectionAbortReason "Reason for connection abort message.";
CM_ SG_ 2632777470 NextPacketNumberToBeSent "Next Packet Number to be sent (TP.CM_CTS)";
CM_ SG_ 2632777470 NumberOfPacketsThatCanBeSent "Number of Packets that can be sent (TP.CM_CTS)";
CM_ SG_ 2632777470 MaximumNumberOfPackets "Maximum number of packets for RTS/CTS message.";
CM_ SG_ 2632777470 TotalNumberOfPackets "Total number of packets for BAM message.Total number of packets received for RTS/CTS message.Total number of packets for RTS/CTS message.";
CM_ SG_ 2632777470 TotalMessageSize "Total message size (in bytes) for BAM message.Total message size (in bytes) for RTS/CTS message.Total message size (in bytes) for RTS/CTS message.";
CM_ BO_ 2561605374 "Tire Pressure Reference Setting";
CM_ SG_ 2561605374 TireLocation "Identifies which tire is associated with the parametric data in this PGN.";
CM_ BO_ 2560818942 "DM32 provides the DTCs and associated timers";
CM_ SG_ 2560818942 DTCTimeUntilDerate "This timer provides the number of hours the malfunction has until the OBD required derate will occur";
CM_ SG_ 2560818942 DTCTotalPreviouslyActiveTime "This timer provides the number of hours the NOx malfunction has been confirmed and previously active";
CM_ SG_ 2560818942 DTCTotalActiveTime "This timer provides the total number of hours the DTC has been confirmed and active";
CM_ SG_ 2560818942 FailureModeIdentifier1 "The FMI defines the type of failure detected in the subsystem identified by an SPN.";
CM_ SG_ 2560818942 SPN1High "SPN #1 (Conversion Version 4)";
CM_ SG_ 2560818942 SPN1 "SPN #1 (Conversion Version 4)";
CM_ BO_ 2566764798 "Diagnostic readiness 3";
CM_ BO_ 2564095742 "Data security";
CM_ BO_ 2566765054 "Tire Pressure Reference Information";
CM_ SG_ 2566765054 TireLocation "Identifies which tire is associated with the parametric data in this PGN.";
CM_ BO_ 2566845694 "Tire Condition";
CM_ SG_ 2566845694 TirePressThresholdDetection_13 "Signal indicating the pressure level of the tire.";
CM_ SG_ 2566845694 TirePressThresholdDetection_12 "Signal indicating the pressure level of the tire.";
CM_ SG_ 2566845694 TirePressThresholdDetection_11 "Signal indicating the pressure level of the tire.";
CM_ SG_ 2566845694 TirePressThresholdDetection_10 "Signal indicating the pressure level of the tire.";
CM_ SG_ 2566845694 TirePressThresholdDetection_01 "Signal indicating the pressure level of the tire.";
CM_ SG_ 2566845694 TirePress_33 "Pressure at which air is contained in cavity formed by tire and rim.";
CM_ SG_ 2566845694 TirePress_32 "Pressure at which air is contained in cavity formed by tire and rim.";
CM_ SG_ 2566845694 TirePress_31 "Pressure at which air is contained in cavity formed by tire and rim.";
CM_ SG_ 2566845694 TirePress_30 "Pressure at which air is contained in cavity formed by tire and rim.";
CM_ SG_ 2566845694 TirePress_23 "Pressure at which air is contained in cavity formed by tire and rim.";
CM_ SG_ 2566845694 TirePress_22 "Pressure at which air is contained in cavity formed by tire and rim.";
CM_ SG_ 2566845694 TirePress_21 "Pressure at which air is contained in cavity formed by tire and rim.";
CM_ SG_ 2566845694 TirePress_20 "Pressure at which air is contained in cavity formed by tire and rim.";
CM_ SG_ 2566845694 TirePress_13 "Pressure at which air is contained in cavity formed by tire and rim.";
CM_ SG_ 2566845694 TirePress_12 "Pressure at which air is contained in cavity formed by tire and rim.";
CM_ SG_ 2566845694 TirePress_11 "Pressure at which air is contained in cavity formed by tire and rim.";
CM_ SG_ 2566845694 TirePress_10 "Pressure at which air is contained in cavity formed by tire and rim.";
CM_ SG_ 2566845694 TireAirLeakageRate_33 "The pressure loss rate of a tire.";
CM_ SG_ 2566845694 TireAirLeakageRate_32 "The pressure loss rate of a tire.";
CM_ SG_ 2566845694 TireAirLeakageRate_31 "The pressure loss rate of a tire.";
CM_ SG_ 2566845694 TireAirLeakageRate_30 "The pressure loss rate of a tire.";
CM_ SG_ 2566845694 TireAirLeakageRate_23 "The pressure loss rate of a tire.";
CM_ SG_ 2566845694 TireAirLeakageRate_22 "The pressure loss rate of a tire.";
CM_ SG_ 2566845694 TireAirLeakageRate_21 "The pressure loss rate of a tire.";
CM_ SG_ 2566845694 TireAirLeakageRate_20 "The pressure loss rate of a tire.";
CM_ SG_ 2566845694 TireAirLeakageRate_13 "The pressure loss rate of a tire.";
CM_ SG_ 2566845694 TireAirLeakageRate_12 "The pressure loss rate of a tire.";
CM_ SG_ 2566845694 TireAirLeakageRate_11 "The pressure loss rate of a tire.";
CM_ SG_ 2566845694 TireAirLeakageRate_10 "The pressure loss rate of a tire.";
CM_ SG_ 2566845694 TireAirLeakageRate_01 "The pressure loss rate of a tire.";
CM_ SG_ 2566845694 TireAirLeakageRate_00 "The pressure loss rate of a tire.";
CM_ SG_ 2566845694 CTIWheelSensorStatus_33 "Indicates whether the wheel is being monitored by the CTI controller.";
CM_ SG_ 2566845694 CTIWheelSensorStatus_32 "Indicates whether the wheel is being monitored by the CTI controller.";
CM_ SG_ 2566845694 CTIWheelSensorStatus_31 "Indicates whether the wheel is being monitored by the CTI controller.";
CM_ SG_ 2566845694 CTIWheelSensorStatus_30 "Indicates whether the wheel is being monitored by the CTI controller.";
CM_ SG_ 2566845694 CTIWheelSensorStatus_23 "Indicates whether the wheel is being monitored by the CTI controller.";
CM_ SG_ 2566845694 CTIWheelSensorStatus_22 "Indicates whether the wheel is being monitored by the CTI controller.";
CM_ SG_ 2566845694 CTIWheelSensorStatus_21 "Indicates whether the wheel is being monitored by the CTI controller.";
CM_ SG_ 2566845694 CTIWheelSensorStatus_20 "Indicates whether the wheel is being monitored by the CTI controller.";
CM_ SG_ 2566845694 CTIWheelSensorStatus_13 "Indicates whether the wheel is being monitored by the CTI controller.";
CM_ SG_ 2566845694 CTIWheelSensorStatus_12 "Indicates whether the wheel is being monitored by the CTI controller.";
CM_ SG_ 2566845694 CTIWheelSensorStatus_11 "Indicates whether the wheel is being monitored by the CTI controller.";
CM_ SG_ 2566845694 CTIWheelSensorStatus_10 "Indicates whether the wheel is being monitored by the CTI controller.";
CM_ SG_ 2566845694 CTIWheelSensorStatus_01 "Indicates whether the wheel is being monitored by the CTI controller.";
CM_ SG_ 2566845694 CTIWheelEndElectricalFault_33 "Indicates the status of electrical fault on CTI wheel interface.";
CM_ SG_ 2566845694 CTIWheelEndElectricalFault_32 "Indicates the status of electrical fault on CTI wheel interface.";
CM_ SG_ 2566845694 CTIWheelEndElectricalFault_31 "Indicates the status of electrical fault on CTI wheel interface.";
CM_ SG_ 2566845694 CTIWheelEndElectricalFault_30 "Indicates the status of electrical fault on CTI wheel interface.";
CM_ SG_ 2566845694 CTIWheelEndElectricalFault_23 "Indicates the status of electrical fault on CTI wheel interface.";
CM_ SG_ 2566845694 CTIWheelEndElectricalFault_22 "Indicates the status of electrical fault on CTI wheel interface.";
CM_ SG_ 2566845694 CTIWheelEndElectricalFault_21 "Indicates the status of electrical fault on CTI wheel interface.";
CM_ SG_ 2566845694 CTIWheelEndElectricalFault_20 "Indicates the status of electrical fault on CTI wheel interface.";
CM_ SG_ 2566845694 CTIWheelEndElectricalFault_13 "Indicates the status of electrical fault on CTI wheel interface.";
CM_ SG_ 2566845694 CTIWheelEndElectricalFault_12 "Indicates the status of electrical fault on CTI wheel interface.";
CM_ SG_ 2566845694 CTIWheelEndElectricalFault_11 "Indicates the status of electrical fault on CTI wheel interface.";
CM_ SG_ 2566845694 CTIWheelEndElectricalFault_10 "Indicates the status of electrical fault on CTI wheel interface.";
CM_ SG_ 2566845694 CTIWheelEndElectricalFault_01 "Indicates the status of electrical fault on CTI wheel interface.";
CM_ SG_ 2566845694 CTITireStatus_33 "Indicates the status of the tire.";
CM_ SG_ 2566845694 CTITireStatus_32 "Indicates the status of the tire.";
CM_ SG_ 2566845694 CTITireStatus_31 "Indicates the status of the tire.";
CM_ SG_ 2566845694 CTITireStatus_30 "Indicates the status of the tire.";
CM_ SG_ 2566845694 CTITireStatus_23 "Indicates the status of the tire.";
CM_ SG_ 2566845694 CTITireStatus_22 "Indicates the status of the tire.";
CM_ SG_ 2566845694 CTITireStatus_21 "Indicates the status of the tire.";
CM_ SG_ 2566845694 CTITireStatus_20 "Indicates the status of the tire.";
CM_ SG_ 2566845694 CTITireStatus_13 "Indicates the status of the tire.";
CM_ SG_ 2566845694 CTITireStatus_12 "Indicates the status of the tire.";
CM_ SG_ 2566845694 CTITireStatus_11 "Indicates the status of the tire.";
CM_ SG_ 2566845694 CTITireStatus_10 "Indicates the status of the tire.";
CM_ SG_ 2566845694 CTITireStatus_01 "Indicates the status of the tire.";
CM_ SG_ 2566845694 TireTemp_11 "Temperature at the surface of the tire sidewall.";
CM_ SG_ 2566845694 TireTemp_33 "Temperature at the surface of the tire sidewall.";
CM_ SG_ 2566845694 TireTemp_32 "Temperature at the surface of the tire sidewall.";
CM_ SG_ 2566845694 TireTemp_31 "Temperature at the surface of the tire sidewall.";
CM_ SG_ 2566845694 TireTemp_30 "Temperature at the surface of the tire sidewall.";
CM_ SG_ 2566845694 TireTemp_23 "Temperature at the surface of the tire sidewall.";
CM_ SG_ 2566845694 TireTemp_22 "Temperature at the surface of the tire sidewall.";
CM_ SG_ 2566845694 TireTemp_21 "Temperature at the surface of the tire sidewall.";
CM_ SG_ 2566845694 TireTemp_20 "Temperature at the surface of the tire sidewall.";
CM_ SG_ 2566845694 TireTemp_13 "Temperature at the surface of the tire sidewall.";
CM_ SG_ 2566845694 TireTemp_12 "Temperature at the surface of the tire sidewall.";
CM_ SG_ 2566845694 TireTemp_10 "Temperature at the surface of the tire sidewall.";
CM_ SG_ 2566845694 TireTemp_01 "Temperature at the surface of the tire sidewall.";
CM_ SG_ 2566845694 TireTemp_00 "Temperature at the surface of the tire sidewall.";
CM_ SG_ 2566845694 TirePressThresholdDetection_33 "Signal indicating the pressure level of the tire.";
CM_ SG_ 2566845694 TirePressThresholdDetection_32 "Signal indicating the pressure level of the tire.";
CM_ SG_ 2566845694 TirePressThresholdDetection_31 "Signal indicating the pressure level of the tire.";
CM_ SG_ 2566845694 TirePressThresholdDetection_30 "Signal indicating the pressure level of the tire.";
CM_ SG_ 2566845694 TirePressThresholdDetection_23 "Signal indicating the pressure level of the tire.";
CM_ SG_ 2566845694 TirePressThresholdDetection_22 "Signal indicating the pressure level of the tire.";
CM_ SG_ 2566845694 TirePressThresholdDetection_21 "Signal indicating the pressure level of the tire.";
CM_ SG_ 2566845694 TirePressThresholdDetection_20 "Signal indicating the pressure level of the tire.";
CM_ SG_ 2566845694 TirePressThresholdDetection_00 "Signal indicating the pressure level of the tire.";
CM_ SG_ 2566845694 TirePress_01 "Pressure at which air is contained in cavity formed by tire and rim.";
CM_ SG_ 2566845694 TirePress_00 "Pressure at which air is contained in cavity formed by tire and rim.";
CM_ SG_ 2566845694 CTIWheelSensorStatus_00 "Indicates whether the wheel is being monitored by the CTI controller.";
CM_ SG_ 2566845694 CTIWheelEndElectricalFault_00 "Indicates the status of electrical fault on CTI wheel interface.";
CM_ SG_ 2566845694 CTITireStatus_00 "Indicates the status of the tire.";
CM_ SG_ 2566845694 TireLocation "Identifies which tire is associated with the parametric data in this PGN.";
CM_ BO_ 2566839038 "Byte: 1 Number of software identification fields";
CM_ SG_ 2566839038 NmbrOfSftwreIdentificationFields "Number of software identification designators represented in the software identification parameter group.";
CM_ SG_ 2566839038 SoftwareIdentification "Software identification of an electronic module. As an example, this parameter may be represented with ASCII characters";
CM_ BO_ 2566768126 "Message for reporting identification and information about the physical ECU and its hardware, such as the ECU's part";
CM_ SG_ 2566768126 ECUType "The type of ECU. One example of a use of the ECU type could be for classifying ECU capabilities, such as I/O.";
CM_ SG_ 2566768126 ECULocation "The location of the ECU within a network.";
CM_ SG_ 2566768126 ECUSerialNumber "The serial number of the physical ECU.";
CM_ SG_ 2566768126 ECUPartNumber "The part number of the physical ECU.";
CM_ BO_ 2566742270 "HB1C provides the system specific individual B1 failure counters";
CM_ SG_ 2566742270 FailureSpecificB1Counter "The Failure Specific B1 Counter provides an individual B1 counter";
CM_ SG_ 2566742270 FailureModeIdentifier1 "The FMI defines the type of failure detected in the subsystem identified by an SPN.";
CM_ SG_ 2566742270 SPN1High "SPN #1 (Conversion Version 4)";
CM_ SG_ 2566742270 SPN1 "SPN #1 (Conversion Version 4)";
CM_ BO_ 2566742526 "Cumulative Continuous MI-System";
CM_ SG_ 2566742526 SysGreatestB1Counter "System Greatest B1 Counter";
CM_ SG_ 2566742526 SysCumulativeContinuousMITime "System Cumulative Continuous MI Time";
CM_ BO_ 2566742782 "Harmonized Global Regulation Description";
CM_ SG_ 2566742782 RegulationDescription "Global Technical Regulation Description";
CM_ BO_ 2566743038 "Harmonized Roadworthiness";
CM_ SG_ 2566743038 SysIncompleteMonitorCount "System Incomplete Monitor Count";
CM_ SG_ 2566743038 SysMalIndActivationMode "System Malfunction Indicator Status";
CM_ SG_ 2566743038 SysMalIndDisplayStrategy "System Malfunction Indicator Display";
CM_ SG_ 2566743038 SysContinuousMalfunctionInd "System Continuous Malfunction Indicator";
CM_ SG_ 2566743038 SysNonRoadworthyCompCount "System Non-Roadworthy Component Count";
CM_ BO_ 2566743294 "Harmonized Roadworthiness ";
CM_ SG_ 2566743294 VehicleCurrentMIAccumTime "Vehicle Current MI Accumulated Time";
CM_ SG_ 2566743294 VehicleIncompleteMonitorCount "Vehicle Incomplete Monitor Count";
CM_ SG_ 2566743294 VehicleMalfunctionIndActMode "Vehicle Malfunction Indicator Status ";
CM_ SG_ 2566743294 VehicleMalfunctionIndStrategy "Vehicle Malfunction Indicator Display Strategy ";
CM_ SG_ 2566743294 VehicleContinuousMalfunctionInd "Vehicle Continuous Malfunction Indicator";
CM_ SG_ 2566743294 VehicleNonRoadworthyCompCount "Vehicle Non-Roadworthy Component Count";
CM_ BO_ 2560687870 "The status of engine operating in the NTE control areas for given pollutants, such as NOx and PM";
CM_ SG_ 2560687870 PMNTEDeficiencyAreaStatus "Status of engine operation within the PM NTE Deficiency Area";
CM_ SG_ 2560687870 MnfcPMNTECarveOutAreaStatus "Status of engine operation within the manufacturer specific PM NTE carve out area";
CM_ SG_ 2560687870 PMNTEControlAreaStatus "Status of engine operation within the bounded region of the engine's torque and speed map.";
CM_ SG_ 2560687870 NOxNTEDeficiencyAreaStatus "Status of engine operation within the NOx NTE Deficiency Area";
CM_ SG_ 2560687870 MnfcNOxNTECarveOutAreaStatus "Status of engine operation within the bounded region of the engine's torque and speed map.";
CM_ SG_ 2560687870 NOxNTEControlAreaStatus "Status of engine operation within the bounded region of the engine's torque and speed map.";
CM_ BO_ 2292317950 "The total engine run time while each of the Emission Increasing Auxiliary Emission Control Devices is active";
CM_ SG_ 2292317950 AECDEngineHours1Timer2 "The total engine running hours recorded in the second timer for the EI-AECD";
CM_ SG_ 2292317950 AECDEngineHours1Timer1 "The total engine running hours recorded in the first timer for the EI-AECD";
CM_ SG_ 2292317950 AECDNumber1 "The manufacturer assigned number for the specific EI-AECD";
CM_ BO_ 2560884478 "This message shall provide the applicable lamp for each individual DTC";
CM_ SG_ 2560884478 DTCWarnLampSupportStatus "Lamp support status";
CM_ SG_ 2560884478 DTCWarnLampSupportFlash "Lamp support status";
CM_ SG_ 2560884478 DTCStopLampSupportStatus "Lamp support status";
CM_ SG_ 2560884478 DTCStopLampSupportFlash "Lamp support status";
CM_ SG_ 2560884478 DTCProtectLampSupportStatus "Lamp support status";
CM_ SG_ 2560884478 DTCProtectLampSupportFlash "Lamp support status";
CM_ SG_ 2560884478 DTCMilSupportStatus "Lamp support status";
CM_ SG_ 2560884478 DTCMilSupportFlash "Lamp support status";
CM_ SG_ 2560884478 DTC1 "Diagnostic Trouble Code";
CM_ BO_ 2560950014 "This message conveys the scaled test results for the applicable test requested in DM7.";
CM_ SG_ 2560950014 TestLimitMinimum "The test value must be greater than or equal to Test Limit Minimum in order for the test to pass";
CM_ SG_ 2560950014 TestLimitMaximum "The test value must be less than or equal to Test Limit Maximum in order for the test to pass.";
CM_ SG_ 2560950014 TestValue "The test value collected during the test.";
CM_ SG_ 2560950014 SlotId "The SLOT Identifer is used to determine the multiplier and offset to be used to scale the test value.";
CM_ SG_ 2560950014 TestIdentifier "Test Identifier";
CM_ SG_ 2560950014 FailureModeIdentifier1 "The FMI defines the type of failure detected in the subsystem identified by an SPN.";
CM_ SG_ 2560950014 SPN1High "SPN #1 (Conversion Version 4)";
CM_ SG_ 2560950014 SPN1 "SPN #1 (Conversion Version 4)";
CM_ BO_ 2566836478 "Test results for non-continously monitored systems.";
CM_ SG_ 2566836478 TestLimitMinimum "The threshold which the test value must be above to pass the test.";
CM_ SG_ 2566836478 TestLimitMaximum "The threshold which the test value must be below to pass the test.";
CM_ SG_ 2566836478 TestValue "The test value collected during the test.";
CM_ SG_ 2566836478 TestType "Identifies the non-continously monitored component identifier that was tested.";
CM_ SG_ 2566836478 TestIdentifier "Designates the test to be run.";
CM_ BO_ 2565078782 "Command non-continously monitored test";
CM_ SG_ 2565078782 SPN1High "SPN #1 (Conversion Version 4)";
CM_ SG_ 2565078782 SPN1 "SPN #1 (Conversion Version 4)";
CM_ SG_ 2565078782 TestIdentifier "Designates the test to be run.";
CM_ SG_ 2565078782 FailureModeIdentifier1 "The FMI defines the type of failure detected in the subsystem identified by an SPN.";
CM_ BO_ 2566836222 "Pending DTCs";
CM_ SG_ 2566836222 FlashRedStopLamp "This parameter provides the capability to flash the RSL (SPN 3039).";
CM_ SG_ 2566836222 FlashProtectLamp "This parameter provides the capability to flash the engine protect lamp (SPN 3041).";
CM_ SG_ 2566836222 FlashMalfuncIndicatorLamp "This parameter provides the capability to flash the MIL (SPN 3038).";
CM_ SG_ 2566836222 FlashAmberWarningLamp "This parameter provides the capability to flash the AWL (SPN 3040). ";
CM_ SG_ 2566836222 MalfunctionIndicatorLampStatus "A lamp used to relay only emissions-related trouble code information.";
CM_ SG_ 2566836222 RedStopLampState "This lamp is uesed to relay trouble code information that is of a severe enought condition that it warrants stopping the vehicle.";
CM_ SG_ 2566836222 AmberWarningLampStatus "This lamp is used to relay trouble code information that is reporting a problem with the vehicle system but the vehicle need
not be immediately stopped.";
CM_ SG_ 2566836222 ProtectLampStatus "This lamp is used to relay trouble code informatio that is reporting a problem with a vehicle system that is most
probably not electronic subsystem related.";
CM_ SG_ 2566836222 DTC5 "Diagnostic Trouble Code";
CM_ SG_ 2566836222 DTC4 "Diagnostic Trouble Code";
CM_ SG_ 2566836222 DTC3 "Diagnostic Trouble Code";
CM_ SG_ 2566836222 DTC2 "Diagnostic Trouble Code";
CM_ SG_ 2566836222 DTC1 "Diagnostic Trouble Code";
CM_ BO_ 2566835966 "Diagnostic readiness 1";
CM_ SG_ 2566835966 OBDCompliance "Identifies the OBD compliance capabilityof the responding controller.";
CM_ SG_ 2566835966 PreviouslyActiveTroubleCodes "Identifies the number of previously active trouble codes that are present in a specific controller.";
CM_ SG_ 2566835966 ActiveTroubleCodes "Identifies the number of active trouble codes that are present in a specific controller.";
CM_ BO_ 2566835710 "Freeze frame parameters";
CM_ SG_ 2566835710 EngIntakeManifold1Press "The gage pressure measurement of the air intake manifold. If there are multiple air pressure sensors in the intake stream,";
CM_ SG_ 2566835710 FreezeFrameLength "The freeze frame length shall be equal to the number of bytes in the required parameters plus the number of bytes in the
manufacturer specific parameters.";
CM_ SG_ 2566835710 EngSpeed "Actual engine speed which is calculated over a minimum crankshaft angle of 720 degrees divided by the number of";
CM_ SG_ 2566835710 EngTorqueMode "State signal which indicates which engine torque mode is currently generating, limiting, or controlling the torque. Note";
CM_ SG_ 2566835710 WheelBasedVehicleSpeed "Speed of the vehicle as calculated from wheel or tailshaft speed.";
CM_ SG_ 2566835710 EngPercentLoadAtCurrentSpeed "The ratio of actual engine percent torque (indicated) to maximum indicated torque available at the current engine speed,";
CM_ SG_ 2566835710 EngCoolantTemp "Temperature of liquid found in engine cooling system.";
CM_ SG_ 2566835710 DTC1 "Diagnostic Trouble Code";
CM_ BO_ 2566835454 "Diagnostic data clear/reset of previously active DTCs.";
CM_ BO_ 2566764542 "Expanded freeze frame.";
CM_ SG_ 2566764542 ExpandedFreezeFrameLength "The freeze frame length shall be equal to the number of bytes in the required parameters plus the number of bytes in the
manufacturer specific parameters.";
CM_ SG_ 2566764542 DTC1 "Diagnostic Trouble Code";
CM_ BO_ 2566764286 "SPN Support. This message is used to identify those SPNs supported by the product for freeze frames and data stream messages.";
CM_ SG_ 2566764286 SPNSupported1High "This parameter defines the SPN(s) that is/are supported for the freeze frame and/or data stream information.";
CM_ SG_ 2566764286 SPNSupportTypeSTR3 "This parameter defines whether the applicable parameter (that is the SPN) is supported in the freeze frame, the data stream or both the freeze frame and data stream.";
CM_ SG_ 2566764286 SPNSupportTypeSTR2 "This parameter defines whether the applicable parameter (that is the SPN) is supported in the freeze frame, the data stream or both the freeze frame and data stream.";
CM_ SG_ 2566764286 SPNSupportTypeEFF3 "This parameter defines whether the applicable parameter (that is the SPN) is supported in the freeze frame, the data stream or both the freeze frame and data stream.";
CM_ SG_ 2566764286 SPNSupportTypeEFF2 "This parameter defines whether the applicable parameter (that is the SPN) is supported in the freeze frame, the data stream or both the freeze frame and data stream.";
CM_ SG_ 2566764286 SPNSupportTypeDS3 "This parameter defines whether the applicable parameter (that is the SPN) is supported in the freeze frame, the data stream or both the freeze frame and data stream.";
CM_ SG_ 2566764286 SPNSupportTypeDS2 "This parameter defines whether the applicable parameter (that is the SPN) is supported in the freeze frame, the data stream or both the freeze frame and data stream.";
CM_ SG_ 2566764286 SPNSupported3High "This parameter defines the SPN(s) that is/are supported for the freeze frame and/or data stream information.";
CM_ SG_ 2566764286 SPNSupported2High "This parameter defines the SPN(s) that is/are supported for the freeze frame and/or data stream information.";
CM_ SG_ 2566764286 SPNSupported3 "This parameter defines the SPN(s) that is/are supported for the freeze frame and/or data stream information.";
CM_ SG_ 2566764286 SPNSupported2 "This parameter defines the SPN(s) that is/are supported for the freeze frame and/or data stream information.";
CM_ SG_ 2566764286 SPNDataLength3 "The number of data bytes associated with the SPN in the Freeze Frame.";
CM_ SG_ 2566764286 SPNSupportTypeSTR1 "This parameter defines whether the applicable parameter (that is the SPN) is supported in the freeze frame, the data stream or both the freeze frame and data stream.";
CM_ SG_ 2566764286 SPNSupportTypeDS1 "This parameter defines whether the applicable parameter (that is the SPN) is supported in the freeze frame, the data stream or both the freeze frame and data stream.";
CM_ SG_ 2566764286 SPNSupportTypeEFF1 "This parameter defines whether the applicable parameter (that is the SPN) is supported in the freeze frame, the data stream or both the freeze frame and data stream.";
CM_ SG_ 2566764286 SPNDataLength2 "The number of data bytes associated with the SPN in the Freeze Frame.";
CM_ SG_ 2566764286 SPNDataLength1 "The number of data bytes associated with the SPN in the Freeze Frame.";
CM_ SG_ 2566764286 SPNSupported1 "This parameter defines the SPN(s) that is/are supported for the freeze frame and/or data stream information.";
CM_ BO_ 2566764030 "Previously active emission related faults.";
CM_ SG_ 2566764030 FlashRedStopLamp "This parameter provides the capability to flash the RSL (SPN 3039).";
CM_ SG_ 2566764030 FlashProtectLamp "This parameter provides the capability to flash the engine protect lamp (SPN 3041).";
CM_ SG_ 2566764030 FlashMalfuncIndicatorLamp "This parameter provides the capability to flash the MIL (SPN 3038).";
CM_ SG_ 2566764030 FlashAmberWarningLamp "This parameter provides the capability to flash the AWL (SPN 3040). ";
CM_ SG_ 2566764030 MalfunctionIndicatorLampStatus "A lamp used to relay only emissions-related trouble code information.";
CM_ SG_ 2566764030 RedStopLampState "This lamp is uesed to relay trouble code information that is of a severe enought condition that it warrants stopping the vehicle.";
CM_ SG_ 2566764030 AmberWarningLampStatus "This lamp is used to relay trouble code information that is reporting a problem with the vehicle system but the vehicle need
not be immediately stopped.";
CM_ SG_ 2566764030 ProtectLampStatus "This lamp is used to relay trouble code informatio that is reporting a problem with a vehicle system that is most
probably not electronic subsystem related.";
CM_ SG_ 2566764030 DTC5 "Diagnostic Trouble Code";
CM_ SG_ 2566764030 DTC4 "Diagnostic Trouble Code";
CM_ SG_ 2566764030 DTC3 "Diagnostic Trouble Code";
CM_ SG_ 2566764030 DTC2 "Diagnostic Trouble Code";
CM_ SG_ 2566764030 DTC1 "Diagnostic Trouble Code";
CM_ BO_ 2562981630 "Individual Clear/Reset of active and previously active DTC.";
CM_ SG_ 2562981630 SPN1 "SPN #1 (Conversion Version 4)";
CM_ SG_ 2562981630 SPN1High "SPN #1 (Conversion Version 4)";
CM_ SG_ 2562981630 FailureModeIdentifier1 "The FMI defines the type of failure detected in the subsystem identified by an SPN.";
CM_ BO_ 2562850558 "Diagnostic readiness 2";
CM_ SG_ 2562850558 TimeSinceDTCsCleared "Time accumulated since DTCs were cleared (via an external test equipment or possibly, a battery disconnect) (SPN=?).";
CM_ SG_ 2562850558 MinutesRunByEngineMILActivated "Accumulated count (in minutes) while the MIL is activated (on) (SPN=?).";
CM_ SG_ 2562850558 DistanceSinceDTCsCleared "Distance accumulated since DTCs were cleared (SPN=?).";
CM_ SG_ 2562850558 DistanceWhileMILisActivated "The kilometers accumulated while the MIL is activated (SPN 3060).";
CM_ BO_ 2562916094 "Monitor Performance Ratio";
CM_ SG_ 2562916094 ApplSysMonitorDenominator "The number of times a vehicle has been operated that constitutes a driving cycle where this Applicable System Monitor could be operated per regulatory requirements (SPN 3068).";
CM_ SG_ 2562916094 ApplSysMonitorNumerator "The number of times a vehicle has been operated such that all conditions necessary for the Applicable System Monitor to detect a malfunction have been encountered (SPN 3067).";
CM_ SG_ 2562916094 SPNofApplSysMonitor "Contain the SPN of the system monitor for which Monitor ratio is being reported (SPN 3066).";
CM_ SG_ 2562916094 OBDMonitoringCondEncountered "Displays the number of times that the vehicle has been operated in the specified OBD monitoring conditions (SPN 3049).";
CM_ SG_ 2562916094 IgnitionCycleCounter "A single counter that defines the number of ignition cycles (SPN 3048).";
BA_DEF_ SG_  "TPMS_Space" INT 0 16777215;
BA_DEF_ BU_  "J1939SpaceSigAttr" STRING ;
BA_DEF_ SG_  "SigType" ENUM  "Default","Range","RangeSigned","ASCII","Discrete","Control","ReferencePGN","DTC","StringDelimiter","StringLength","StringLengthControl";
BA_DEF_ SG_  "GenSigStartValue" INT 0 10000;
BA_DEF_ SG_  "GenSigSendType" ENUM  "Cyclic","OnWrite","OnWriteWithRepetition","OnChange","OnChangeWithRepetition","IfActive","IfActiveWithRepetition","NoSigSendType";
BA_DEF_ SG_  "GenSigILSupport" ENUM  "No","Yes";
BA_DEF_ SG_  "GenSigEVName" STRING ;
BA_DEF_ SG_  "SPN" INT 0 524287;
BA_DEF_ SG_  "SAEDocument" STRING ;
BA_DEF_ BO_  "GenMsgILSupport" ENUM  "No","Yes";
BA_DEF_ BO_  "GenMsgRequestable" INT 0 1;
BA_DEF_ BO_  "GenMsgSendType" ENUM  "cyclic","NotUsed","NotUsed","NotUsed","NotUsed","NotUsed","NotUsed","IfActive","noMsgSendType";
BA_DEF_ BO_  "VFrameFormat" ENUM  "StandardCAN","ExtendedCAN","reserved","J1939PG";
BA_DEF_ BO_  "SingleFrame" INT 0 1;
BA_DEF_ BO_  "GenMsgCycleTime" INT 0 3600000;
BA_DEF_ BO_  "SAE_Document" STRING ;
BA_DEF_ BU_  "NmStationAddress" INT 0 255;
BA_DEF_ BU_  "NmJ1939AAC" INT 0 1;
BA_DEF_ BU_  "NmJ1939IndustryGroup" INT 0 7;
BA_DEF_ BU_  "NmJ1939System" INT 0 127;
BA_DEF_ BU_  "NmJ1939SystemInstance" INT 0 15;
BA_DEF_ BU_  "NmJ1939Function" INT 0 255;
BA_DEF_ BU_  "NmJ1939FunctionInstance" INT 0 7;
BA_DEF_ BU_  "NmJ1939ECUInstance" INT 0 7;
BA_DEF_ BU_  "NmJ1939ManufacturerCode" INT 0 2047;
BA_DEF_ BU_  "NmJ1939IdentityNumber" INT 0 2097151;
BA_DEF_ BU_  "ECU" STRING ;
BA_DEF_  "DatabaseVersion" STRING ;
BA_DEF_  "BusType" STRING ;
BA_DEF_  "ProtocolType" STRING ;
BA_DEF_  "SAE_J1939_75_SpecVersion" STRING ;
BA_DEF_  "SAE_J1939_21_SpecVersion" STRING ;
BA_DEF_  "SAE_J1939_73_SpecVersion" STRING ;
BA_DEF_  "SAE_J1939_71_SpecVersion" STRING ;
BA_DEF_ SG_  "SystemSignalLongSymbol" STRING ;
BA_DEF_DEF_  "TPMS_Space" 0;
BA_DEF_DEF_  "J1939SpaceSigAttr" "";
BA_DEF_DEF_  "SigType" "Default";
BA_DEF_DEF_  "GenSigStartValue" 0;
BA_DEF_DEF_  "GenSigSendType" "NoSigSendType";
BA_DEF_DEF_  "GenSigILSupport" "Yes";
BA_DEF_DEF_  "GenSigEVName" "Env@Nodename_@Signame";
BA_DEF_DEF_  "SPN" 0;
BA_DEF_DEF_  "SAEDocument" "";
BA_DEF_DEF_  "GenMsgILSupport" "Yes";
BA_DEF_DEF_  "GenMsgRequestable" 1;
BA_DEF_DEF_  "GenMsgSendType" "noMsgSendType";
BA_DEF_DEF_  "VFrameFormat" "J1939PG";
BA_DEF_DEF_  "SingleFrame" 1;
BA_DEF_DEF_  "GenMsgCycleTime" 0;
BA_DEF_DEF_  "SAE_Document" "";
BA_DEF_DEF_  "NmStationAddress" 254;
BA_DEF_DEF_  "NmJ1939AAC" 0;
BA_DEF_DEF_  "NmJ1939IndustryGroup" 0;
BA_DEF_DEF_  "NmJ1939System" 0;
BA_DEF_DEF_  "NmJ1939SystemInstance" 0;
BA_DEF_DEF_  "NmJ1939Function" 0;
BA_DEF_DEF_  "NmJ1939FunctionInstance" 0;
BA_DEF_DEF_  "NmJ1939ECUInstance" 0;
BA_DEF_DEF_  "NmJ1939ManufacturerCode" 0;
BA_DEF_DEF_  "NmJ1939IdentityNumber" 0;
BA_DEF_DEF_  "ECU" "";
BA_DEF_DEF_  "DatabaseVersion" "";
BA_DEF_DEF_  "BusType" "";
BA_DEF_DEF_  "ProtocolType" "";
BA_DEF_DEF_  "SAE_J1939_75_SpecVersion" "";
BA_DEF_DEF_  "SAE_J1939_21_SpecVersion" "";
BA_DEF_DEF_  "SAE_J1939_73_SpecVersion" "";
BA_DEF_DEF_  "SAE_J1939_71_SpecVersion" "";
BA_DEF_DEF_  "SystemSignalLongSymbol" "";
BA_ "DatabaseVersion" "7.5";
BA_ "BusType" "CAN";
BA_ "ProtocolType" "J1939";
BA_ "SAE_J1939_75_SpecVersion" "2005-10";
BA_ "SAE_J1939_21_SpecVersion" "2006-10";
BA_ "SAE_J1939_73_SpecVersion" "2010-10";
BA_ "SAE_J1939_71_SpecVersion" "2010-10";
BA_ "J1939SpaceSigAttr" BU_ TPMS "TPMS_Space=0x80";
BA_ "ECU" BU_ TPMS "TPMS";
BA_ "NmJ1939IdentityNumber" BU_ TPMS 1038;
BA_ "NmJ1939ManufacturerCode" BU_ TPMS 1861;
BA_ "NmStationAddress" BU_ TPMS 51;
BA_ "NmJ1939Function" BU_ TPMS 38;
BA_ "SAE_Document" BO_ 2565537534 "J1939-21";
BA_ "SAE_Document" BO_ 2632711934 "J1939-21";
BA_ "SAE_Document" BO_ 2632777470 "J1939-21";
BA_ "SAE_Document" BO_ 2561605374 "J1939-71";
BA_ "SAE_Document" BO_ 2560818942 "J1939_73";
BA_ "SAE_Document" BO_ 2566764798 "J1939-73";
BA_ "SAE_Document" BO_ 2564095742 "J1939-73";
BA_ "SAE_Document" BO_ 2566765054 "J1939-71";
BA_ "GenMsgSendType" BO_ 2566845694 0;
BA_ "GenMsgCycleTime" BO_ 2566845694 10000;
BA_ "SAE_Document" BO_ 2566845694 "J1939-71";
BA_ "SAE_Document" BO_ 2566839038 "J1939-71";
BA_ "SAE_Document" BO_ 2566768126 "J1939-71";
BA_ "SAE_Document" BO_ 2566742270 "J1939_73";
BA_ "SAE_Document" BO_ 2566742526 "J1939_73";
BA_ "SAE_Document" BO_ 2566742782 "J1939_73";
BA_ "SAE_Document" BO_ 2566743038 "J1939_73";
BA_ "SAE_Document" BO_ 2566743294 "J1939_73";
BA_ "SAE_Document" BO_ 2560687870 "J1939_73";
BA_ "SAE_Document" BO_ 2292317950 "J1939_73";
BA_ "SAE_Document" BO_ 2560884478 "J1939_73";
BA_ "SAE_Document" BO_ 2560950014 "J1939_73";
BA_ "SAE_Document" BO_ 2566836478 "J1939-73";
BA_ "SAE_Document" BO_ 2565078782 "J1939-73";
BA_ "SAE_Document" BO_ 2566836222 "J1939-73";
BA_ "SAE_Document" BO_ 2566835966 "J1939-73";
BA_ "SAE_Document" BO_ 2566835710 "J1939-73";
BA_ "SAE_Document" BO_ 2566835454 "J1939-73";
BA_ "SAE_Document" BO_ 2566764542 "J1939-73";
BA_ "SAE_Document" BO_ 2566764286 "J1939-73";
BA_ "SAE_Document" BO_ 2566764030 "J1939-73";
BA_ "SAE_Document" BO_ 2562981630 "J1939-73";
BA_ "SAE_Document" BO_ 2562850558 "J1939-73";
BA_ "SAE_Document" BO_ 2562916094 "J1939-73";
BA_ "SigType" SG_ 3221225472 ParameterGroupNumber 6;
BA_ "SPN" SG_ 3221225472 ParameterGroupNumber 2574;
BA_ "SAEDocument" SG_ 3221225472 ParameterGroupNumber "J1939-21";
BA_ "SigType" SG_ 3221225472 TireTemp 1;
BA_ "SPN" SG_ 3221225472 TireTemp 242;
BA_ "SAEDocument" SG_ 3221225472 TireTemp "J1939-71";
BA_ "SPN" SG_ 3221225472 TirePressThresholdDetection 2587;
BA_ "SAEDocument" SG_ 3221225472 TirePressThresholdDetection "J1939-71";
BA_ "SigType" SG_ 3221225472 TirePress 1;
BA_ "SPN" SG_ 3221225472 TirePress 241;
BA_ "SAEDocument" SG_ 3221225472 TirePress "J1939-71";
BA_ "SigType" SG_ 3221225472 TrailerWeight 1;
BA_ "SPN" SG_ 3221225472 TrailerWeight 180;
BA_ "SAEDocument" SG_ 3221225472 TrailerWeight "J1939-71";
BA_ "SigType" SG_ 3221225472 TireAirLeakageRate 1;
BA_ "SPN" SG_ 3221225472 TireAirLeakageRate 2586;
BA_ "SAEDocument" SG_ 3221225472 TireAirLeakageRate "J1939-71";
BA_ "SPN" SG_ 3221225472 ReferenceTirePressSetting 3193;
BA_ "SAEDocument" SG_ 3221225472 ReferenceTirePressSetting "J1939-71";
BA_ "SPN" SG_ 3221225472 ReferenceTirePress 3191;
BA_ "SAEDocument" SG_ 3221225472 ReferenceTirePress "J1939-71";
BA_ "SigType" SG_ 3221225472 CTIWheelEndElectricalFault 4;
BA_ "SPN" SG_ 3221225472 CTIWheelEndElectricalFault 1697;
BA_ "SAEDocument" SG_ 3221225472 CTIWheelEndElectricalFault "J1939-71";
BA_ "SigType" SG_ 3221225472 CTITireStatus 4;
BA_ "SPN" SG_ 3221225472 CTITireStatus 1698;
BA_ "SAEDocument" SG_ 3221225472 CTITireStatus "J1939-71";
BA_ "SigType" SG_ 3221225472 CTIWheelSensorStatus 4;
BA_ "SPN" SG_ 3221225472 CTIWheelSensorStatus 1699;
BA_ "SAEDocument" SG_ 3221225472 CTIWheelSensorStatus "J1939-71";
BA_ "SigType" SG_ 3221225472 EngTurningGearEngaged 4;
BA_ "SPN" SG_ 3221225472 EngTurningGearEngaged 1206;
BA_ "SAEDocument" SG_ 3221225472 EngTurningGearEngaged "J1939-71";
BA_ "SigType" SG_ 2565537534 ParameterGroupNumber 6;
BA_ "SPN" SG_ 2565537534 ParameterGroupNumber 2574;
BA_ "SAEDocument" SG_ 2565537534 ParameterGroupNumber "J1939-21";
BA_ "SAEDocument" SG_ 2632777470 TotalNumberOfPacketsEoMA "J1939-21";
BA_ "SAEDocument" SG_ 2632777470 TotalMessageSizeEoMA "J1939-21";
BA_ "SAEDocument" SG_ 2632777470 TotalMessageSizeBAM "J1939-21";
BA_ "SAEDocument" SG_ 2632777470 TotalNumberOfPacketsBAM "J1939-21";
BA_ "SAEDocument" SG_ 2632777470 ConnectionAbortReason "J1939-21";
BA_ "SPN" SG_ 2632777470 ConnectionAbortReason 2570;
BA_ "SAEDocument" SG_ 2632777470 NextPacketNumberToBeSent "J1939-21";
BA_ "SPN" SG_ 2632777470 NextPacketNumberToBeSent 2562;
BA_ "SAEDocument" SG_ 2632777470 NumberOfPacketsThatCanBeSent "J1939-21";
BA_ "SPN" SG_ 2632777470 NumberOfPacketsThatCanBeSent 2561;
BA_ "SAEDocument" SG_ 2632777470 PGNumber "J1939-21";
BA_ "SPN" SG_ 2632777470 PGNumber 2560;
BA_ "SigType" SG_ 2632777470 PGNumber 6;
BA_ "SAEDocument" SG_ 2632777470 MaximumNumberOfPackets "J1939-21";
BA_ "SPN" SG_ 2632777470 MaximumNumberOfPackets 2559;
BA_ "SAEDocument" SG_ 2632777470 TotalNumberOfPackets "J1939-21";
BA_ "SPN" SG_ 2632777470 TotalNumberOfPackets 2558;
BA_ "SAEDocument" SG_ 2632777470 TotalMessageSize "J1939-21";
BA_ "SPN" SG_ 2632777470 TotalMessageSize 2557;
BA_ "SAEDocument" SG_ 2632777470 ControlByte "J1939-21";
BA_ "SPN" SG_ 2632777470 ControlByte 2556;
BA_ "SigType" SG_ 2561605374 TireLocation 1;
BA_ "SPN" SG_ 2561605374 TireLocation 3190;
BA_ "SAEDocument" SG_ 2561605374 TireLocation "J1939-71";
BA_ "SigType" SG_ 2561605374 ReferenceTirePressSetting_00 1;
BA_ "SPN" SG_ 2561605374 ReferenceTirePressSetting_00 521800;
BA_ "SigType" SG_ 2561605374 ReferenceTirePressSetting_01 1;
BA_ "SPN" SG_ 2561605374 ReferenceTirePressSetting_01 521801;
BA_ "SigType" SG_ 2561605374 ReferenceTirePressSetting_10 1;
BA_ "SPN" SG_ 2561605374 ReferenceTirePressSetting_10 521810;
BA_ "SigType" SG_ 2561605374 ReferenceTirePressSetting_11 1;
BA_ "SPN" SG_ 2561605374 ReferenceTirePressSetting_11 521811;
BA_ "SigType" SG_ 2561605374 ReferenceTirePressSetting_12 1;
BA_ "SPN" SG_ 2561605374 ReferenceTirePressSetting_12 521812;
BA_ "SigType" SG_ 2561605374 ReferenceTirePressSetting_13 1;
BA_ "SPN" SG_ 2561605374 ReferenceTirePressSetting_13 521813;
BA_ "SigType" SG_ 2561605374 ReferenceTirePressSetting_20 1;
BA_ "SPN" SG_ 2561605374 ReferenceTirePressSetting_20 521820;
BA_ "SigType" SG_ 2561605374 ReferenceTirePressSetting_21 1;
BA_ "SPN" SG_ 2561605374 ReferenceTirePressSetting_21 521821;
BA_ "SigType" SG_ 2561605374 ReferenceTirePressSetting_22 1;
BA_ "SPN" SG_ 2561605374 ReferenceTirePressSetting_22 521822;
BA_ "SigType" SG_ 2561605374 ReferenceTirePressSetting_23 1;
BA_ "SPN" SG_ 2561605374 ReferenceTirePressSetting_23 521823;
BA_ "SigType" SG_ 2561605374 ReferenceTirePressSetting_30 1;
BA_ "SPN" SG_ 2561605374 ReferenceTirePressSetting_30 521830;
BA_ "SigType" SG_ 2561605374 ReferenceTirePressSetting_31 1;
BA_ "SPN" SG_ 2561605374 ReferenceTirePressSetting_31 521831;
BA_ "SigType" SG_ 2561605374 ReferenceTirePressSetting_32 1;
BA_ "SPN" SG_ 2561605374 ReferenceTirePressSetting_32 521832;
BA_ "SigType" SG_ 2561605374 ReferenceTirePressSetting_33 1;
BA_ "SPN" SG_ 2561605374 ReferenceTirePressSetting_33 521833;
BA_ "SigType" SG_ 2560818942 DTCTimeUntilDerate 1;
BA_ "SPN" SG_ 2560818942 DTCTimeUntilDerate 4123;
BA_ "SAEDocument" SG_ 2560818942 DTCTimeUntilDerate "J1939_73";
BA_ "SigType" SG_ 2560818942 DTCTotalPreviouslyActiveTime 1;
BA_ "SPN" SG_ 2560818942 DTCTotalPreviouslyActiveTime 4122;
BA_ "SAEDocument" SG_ 2560818942 DTCTotalPreviouslyActiveTime "J1939_73";
BA_ "SigType" SG_ 2560818942 DTCTotalActiveTime 1;
BA_ "SPN" SG_ 2560818942 DTCTotalActiveTime 4121;
BA_ "SAEDocument" SG_ 2560818942 DTCTotalActiveTime "J1939_73";
BA_ "SPN" SG_ 2560818942 FailureModeIdentifier1 1215;
BA_ "SAEDocument" SG_ 2560818942 FailureModeIdentifier1 "J1939-73";
BA_ "SAEDocument" SG_ 2560818942 SPN1High "J1939-73";
BA_ "SPN" SG_ 2560818942 SPN1 1214;
BA_ "SAEDocument" SG_ 2560818942 SPN1 "J1939-73";
BA_ "SystemSignalLongSymbol" SG_ 2566764798 NOxConvertingCatalystAdsorberCom "NOxConvertingCatalystAdsorberCompleted";
BA_ "SystemSignalLongSymbol" SG_ 2566764798 NOxConvertingCatalystAdsorberEna "NOxConvertingCatalystAdsorberEnabled";
BA_ "SystemSignalLongSymbol" SG_ 2566764798 BoostPressureControlSystemComple "BoostPressureControlSystemCompleted";
BA_ "SystemSignalLongSymbol" SG_ 2566764798 BoostPressureControlSystemEnable "BoostPressureControlSystemEnabled";
BA_ "SAEDocument" SG_ 2566764798 MisfireMonitoringComplete "J1939-73";
BA_ "SAEDocument" SG_ 2566764798 MisfireMonitoringEnabled "J1939-73";
BA_ "SAEDocument" SG_ 2566764798 FuelSystemMonitoringEnabled "J1939-73";
BA_ "SAEDocument" SG_ 2566764798 ComprehensiveComptMonComplete "J1939-73";
BA_ "SAEDocument" SG_ 2566764798 ComprehensiveCompMonEnabled "J1939-73";
BA_ "SAEDocument" SG_ 2566764798 SecondAirSystemMonComplete "J1939-73";
BA_ "SAEDocument" SG_ 2566764798 SecondAirSystemMonEnabled "J1939-73";
BA_ "SAEDocument" SG_ 2566764798 OxygenSensorMonComplete "J1939-73";
BA_ "SAEDocument" SG_ 2566764798 OxygenSensorMonEnabled "J1939-73";
BA_ "SAEDocument" SG_ 2566764798 OxygenSensorHeaterMonComplete "J1939-73";
BA_ "SAEDocument" SG_ 2566764798 OxygenSensorHeaterMonEnabled "J1939-73";
BA_ "SAEDocument" SG_ 2566764798 HeatedCatalystMonComplete "J1939-73";
BA_ "SAEDocument" SG_ 2566764798 HeatedCatalystMonEnabled "J1939-73";
BA_ "SAEDocument" SG_ 2566764798 EvaporativeSystemMonComplete "J1939-73";
BA_ "SAEDocument" SG_ 2566764798 EvaporativeSystemMonEnabled "J1939-73";
BA_ "SAEDocument" SG_ 2566764798 EGRSystemMonitoringComplete "J1939-73";
BA_ "SAEDocument" SG_ 2566764798 EGRSystemMonitoringEnabled "J1939-73";
BA_ "SAEDocument" SG_ 2566764798 ColdStartAidSystemMonComplete "J1939-73";
BA_ "SAEDocument" SG_ 2566764798 ColdStartAidSystemMonEnabled "J1939-73";
BA_ "SAEDocument" SG_ 2566764798 CatalystMonComplete "J1939-73";
BA_ "SAEDocument" SG_ 2566764798 CatalystMonEnabled "J1939-73";
BA_ "SAEDocument" SG_ 2566764798 ACSystemRefrigerantMonComplete "J1939-73";
BA_ "SAEDocument" SG_ 2566764798 ACSystemRefrigerantMonEnabled "J1939-73";
BA_ "SAEDocument" SG_ 2566764798 FuelSystemMonitoringComplete "J1939-73";
BA_ "SPN" SG_ 2566764798 NumOfWarmUpsSinceDTCsCleared 3302;
BA_ "SAEDocument" SG_ 2566764798 NumOfWarmUpsSinceDTCsCleared "J1939-73";
BA_ "SPN" SG_ 2566764798 TimeSinceEngineStart 3301;
BA_ "SAEDocument" SG_ 2566764798 TimeSinceEngineStart "J1939-73";
BA_ "SAEDocument" SG_ 2564095742 SecurityEntityLengthHigh "J1939-73";
BA_ "SPN" SG_ 2564095742 SecurityEntityType 1479;
BA_ "SAEDocument" SG_ 2564095742 SecurityEntityType "J1939-73";
BA_ "SPN" SG_ 2564095742 SecurityEntityLength 1596;
BA_ "SAEDocument" SG_ 2564095742 SecurityEntityLength "J1939-73";
BA_ "SigType" SG_ 2566765054 ReferenceTirePress_33 1;
BA_ "SPN" SG_ 2566765054 ReferenceTirePress_33 521933;
BA_ "SigType" SG_ 2566765054 ReferenceTirePress_32 1;
BA_ "SPN" SG_ 2566765054 ReferenceTirePress_32 521932;
BA_ "SigType" SG_ 2566765054 ReferenceTirePress_31 1;
BA_ "SPN" SG_ 2566765054 ReferenceTirePress_31 521931;
BA_ "SigType" SG_ 2566765054 ReferenceTirePress_30 1;
BA_ "SPN" SG_ 2566765054 ReferenceTirePress_30 521930;
BA_ "SigType" SG_ 2566765054 ReferenceTirePress_23 1;
BA_ "SPN" SG_ 2566765054 ReferenceTirePress_23 521923;
BA_ "SigType" SG_ 2566765054 ReferenceTirePress_22 1;
BA_ "SPN" SG_ 2566765054 ReferenceTirePress_22 521922;
BA_ "SigType" SG_ 2566765054 ReferenceTirePress_21 1;
BA_ "SPN" SG_ 2566765054 ReferenceTirePress_21 521921;
BA_ "TPMS_Space" SG_ 2566765054 ReferenceTirePress_21 18;
BA_ "SigType" SG_ 2566765054 ReferenceTirePress_20 1;
BA_ "SPN" SG_ 2566765054 ReferenceTirePress_20 521920;
BA_ "TPMS_Space" SG_ 2566765054 ReferenceTirePress_20 17;
BA_ "SigType" SG_ 2566765054 ReferenceTirePress_13 1;
BA_ "SPN" SG_ 2566765054 ReferenceTirePress_13 521913;
BA_ "SigType" SG_ 2566765054 ReferenceTirePress_12 1;
BA_ "SPN" SG_ 2566765054 ReferenceTirePress_12 521912;
BA_ "SigType" SG_ 2566765054 ReferenceTirePress_11 1;
BA_ "SPN" SG_ 2566765054 ReferenceTirePress_11 521911;
BA_ "TPMS_Space" SG_ 2566765054 ReferenceTirePress_11 16;
BA_ "SigType" SG_ 2566765054 ReferenceTirePress_10 1;
BA_ "SPN" SG_ 2566765054 ReferenceTirePress_10 521910;
BA_ "TPMS_Space" SG_ 2566765054 ReferenceTirePress_10 15;
BA_ "SigType" SG_ 2566765054 ReferenceTirePress_01 1;
BA_ "SPN" SG_ 2566765054 ReferenceTirePress_01 521901;
BA_ "TPMS_Space" SG_ 2566765054 ReferenceTirePress_01 14;
BA_ "SigType" SG_ 2566765054 ReferenceTirePress_00 1;
BA_ "SPN" SG_ 2566765054 ReferenceTirePress_00 521900;
BA_ "TPMS_Space" SG_ 2566765054 ReferenceTirePress_00 13;
BA_ "SigType" SG_ 2566765054 TireLocation 1;
BA_ "SPN" SG_ 2566765054 TireLocation 3190;
BA_ "SAEDocument" SG_ 2566765054 TireLocation "J1939-71";
BA_ "SPN" SG_ 2566845694 TirePressThresholdDetection_13 521613;
BA_ "SPN" SG_ 2566845694 TirePressThresholdDetection_12 521612;
BA_ "SPN" SG_ 2566845694 TirePressThresholdDetection_11 521611;
BA_ "SPN" SG_ 2566845694 TirePressThresholdDetection_10 521610;
BA_ "SPN" SG_ 2566845694 TirePressThresholdDetection_01 521601;
BA_ "SigType" SG_ 2566845694 TirePress_33 1;
BA_ "SPN" SG_ 2566845694 TirePress_33 521033;
BA_ "SigType" SG_ 2566845694 TirePress_32 1;
BA_ "SPN" SG_ 2566845694 TirePress_32 521032;
BA_ "SigType" SG_ 2566845694 TirePress_31 1;
BA_ "SPN" SG_ 2566845694 TirePress_31 521031;
BA_ "SigType" SG_ 2566845694 TirePress_30 1;
BA_ "SPN" SG_ 2566845694 TirePress_30 521030;
BA_ "SigType" SG_ 2566845694 TirePress_23 1;
BA_ "SPN" SG_ 2566845694 TirePress_23 521023;
BA_ "SigType" SG_ 2566845694 TirePress_22 1;
BA_ "SPN" SG_ 2566845694 TirePress_22 521022;
BA_ "SigType" SG_ 2566845694 TirePress_21 1;
BA_ "SPN" SG_ 2566845694 TirePress_21 521021;
BA_ "TPMS_Space" SG_ 2566845694 TirePress_21 6;
BA_ "SigType" SG_ 2566845694 TirePress_20 1;
BA_ "SPN" SG_ 2566845694 TirePress_20 521020;
BA_ "TPMS_Space" SG_ 2566845694 TirePress_20 5;
BA_ "SigType" SG_ 2566845694 TirePress_13 1;
BA_ "SPN" SG_ 2566845694 TirePress_13 521013;
BA_ "SigType" SG_ 2566845694 TirePress_12 1;
BA_ "SPN" SG_ 2566845694 TirePress_12 521012;
BA_ "SigType" SG_ 2566845694 TirePress_11 1;
BA_ "SPN" SG_ 2566845694 TirePress_11 521011;
BA_ "TPMS_Space" SG_ 2566845694 TirePress_11 4;
BA_ "SigType" SG_ 2566845694 TirePress_10 1;
BA_ "SPN" SG_ 2566845694 TirePress_10 521010;
BA_ "TPMS_Space" SG_ 2566845694 TirePress_10 3;
BA_ "SigType" SG_ 2566845694 TireAirLeakageRate_33 1;
BA_ "SPN" SG_ 2566845694 TireAirLeakageRate_33 521533;
BA_ "SigType" SG_ 2566845694 TireAirLeakageRate_32 1;
BA_ "SPN" SG_ 2566845694 TireAirLeakageRate_32 521532;
BA_ "SigType" SG_ 2566845694 TireAirLeakageRate_31 1;
BA_ "SPN" SG_ 2566845694 TireAirLeakageRate_31 521531;
BA_ "SigType" SG_ 2566845694 TireAirLeakageRate_30 1;
BA_ "SPN" SG_ 2566845694 TireAirLeakageRate_30 521530;
BA_ "SigType" SG_ 2566845694 TireAirLeakageRate_23 1;
BA_ "SPN" SG_ 2566845694 TireAirLeakageRate_23 521523;
BA_ "SigType" SG_ 2566845694 TireAirLeakageRate_22 1;
BA_ "SPN" SG_ 2566845694 TireAirLeakageRate_22 521522;
BA_ "SigType" SG_ 2566845694 TireAirLeakageRate_21 1;
BA_ "SPN" SG_ 2566845694 TireAirLeakageRate_21 521521;
BA_ "SigType" SG_ 2566845694 TireAirLeakageRate_20 1;
BA_ "SPN" SG_ 2566845694 TireAirLeakageRate_20 521520;
BA_ "SigType" SG_ 2566845694 TireAirLeakageRate_13 1;
BA_ "SPN" SG_ 2566845694 TireAirLeakageRate_13 521513;
BA_ "SigType" SG_ 2566845694 TireAirLeakageRate_12 1;
BA_ "SPN" SG_ 2566845694 TireAirLeakageRate_12 521512;
BA_ "SigType" SG_ 2566845694 TireAirLeakageRate_11 1;
BA_ "SPN" SG_ 2566845694 TireAirLeakageRate_11 521511;
BA_ "SigType" SG_ 2566845694 TireAirLeakageRate_10 1;
BA_ "SPN" SG_ 2566845694 TireAirLeakageRate_10 521510;
BA_ "SigType" SG_ 2566845694 TireAirLeakageRate_01 1;
BA_ "SPN" SG_ 2566845694 TireAirLeakageRate_01 521501;
BA_ "SigType" SG_ 2566845694 TireAirLeakageRate_00 1;
BA_ "SPN" SG_ 2566845694 TireAirLeakageRate_00 521500;
BA_ "SigType" SG_ 2566845694 CTIWheelSensorStatus_33 4;
BA_ "SPN" SG_ 2566845694 CTIWheelSensorStatus_33 521433;
BA_ "SigType" SG_ 2566845694 CTIWheelSensorStatus_32 4;
BA_ "SPN" SG_ 2566845694 CTIWheelSensorStatus_32 521432;
BA_ "SigType" SG_ 2566845694 CTIWheelSensorStatus_31 4;
BA_ "SPN" SG_ 2566845694 CTIWheelSensorStatus_31 521431;
BA_ "SigType" SG_ 2566845694 CTIWheelSensorStatus_30 4;
BA_ "SPN" SG_ 2566845694 CTIWheelSensorStatus_30 521430;
BA_ "SigType" SG_ 2566845694 CTIWheelSensorStatus_23 4;
BA_ "SPN" SG_ 2566845694 CTIWheelSensorStatus_23 521423;
BA_ "SigType" SG_ 2566845694 CTIWheelSensorStatus_22 4;
BA_ "SPN" SG_ 2566845694 CTIWheelSensorStatus_22 521422;
BA_ "SigType" SG_ 2566845694 CTIWheelSensorStatus_21 4;
BA_ "SPN" SG_ 2566845694 CTIWheelSensorStatus_21 521421;
BA_ "SigType" SG_ 2566845694 CTIWheelSensorStatus_20 4;
BA_ "SPN" SG_ 2566845694 CTIWheelSensorStatus_20 521420;
BA_ "SigType" SG_ 2566845694 CTIWheelSensorStatus_13 4;
BA_ "SPN" SG_ 2566845694 CTIWheelSensorStatus_13 521413;
BA_ "SigType" SG_ 2566845694 CTIWheelSensorStatus_12 4;
BA_ "SPN" SG_ 2566845694 CTIWheelSensorStatus_12 521412;
BA_ "SigType" SG_ 2566845694 CTIWheelSensorStatus_11 4;
BA_ "SPN" SG_ 2566845694 CTIWheelSensorStatus_11 521411;
BA_ "SigType" SG_ 2566845694 CTIWheelSensorStatus_10 4;
BA_ "SPN" SG_ 2566845694 CTIWheelSensorStatus_10 521410;
BA_ "SigType" SG_ 2566845694 CTIWheelSensorStatus_01 4;
BA_ "SPN" SG_ 2566845694 CTIWheelSensorStatus_01 521401;
BA_ "SigType" SG_ 2566845694 CTIWheelEndElectricalFault_33 4;
BA_ "SPN" SG_ 2566845694 CTIWheelEndElectricalFault_33 521233;
BA_ "SigType" SG_ 2566845694 CTIWheelEndElectricalFault_32 4;
BA_ "SPN" SG_ 2566845694 CTIWheelEndElectricalFault_32 521232;
BA_ "SigType" SG_ 2566845694 CTIWheelEndElectricalFault_31 4;
BA_ "SPN" SG_ 2566845694 CTIWheelEndElectricalFault_31 521231;
BA_ "SigType" SG_ 2566845694 CTIWheelEndElectricalFault_30 4;
BA_ "SPN" SG_ 2566845694 CTIWheelEndElectricalFault_30 521230;
BA_ "SigType" SG_ 2566845694 CTIWheelEndElectricalFault_23 4;
BA_ "SPN" SG_ 2566845694 CTIWheelEndElectricalFault_23 521223;
BA_ "SigType" SG_ 2566845694 CTIWheelEndElectricalFault_22 4;
BA_ "SPN" SG_ 2566845694 CTIWheelEndElectricalFault_22 521222;
BA_ "SigType" SG_ 2566845694 CTIWheelEndElectricalFault_21 4;
BA_ "SPN" SG_ 2566845694 CTIWheelEndElectricalFault_21 521221;
BA_ "SigType" SG_ 2566845694 CTIWheelEndElectricalFault_20 4;
BA_ "SPN" SG_ 2566845694 CTIWheelEndElectricalFault_20 521220;
BA_ "SigType" SG_ 2566845694 CTIWheelEndElectricalFault_13 4;
BA_ "SPN" SG_ 2566845694 CTIWheelEndElectricalFault_13 521213;
BA_ "SigType" SG_ 2566845694 CTIWheelEndElectricalFault_12 4;
BA_ "SPN" SG_ 2566845694 CTIWheelEndElectricalFault_12 521212;
BA_ "SigType" SG_ 2566845694 CTIWheelEndElectricalFault_11 4;
BA_ "SPN" SG_ 2566845694 CTIWheelEndElectricalFault_11 521211;
BA_ "SigType" SG_ 2566845694 CTIWheelEndElectricalFault_10 4;
BA_ "SPN" SG_ 2566845694 CTIWheelEndElectricalFault_10 521210;
BA_ "SigType" SG_ 2566845694 CTIWheelEndElectricalFault_01 4;
BA_ "SPN" SG_ 2566845694 CTIWheelEndElectricalFault_01 521201;
BA_ "SigType" SG_ 2566845694 CTITireStatus_33 4;
BA_ "SPN" SG_ 2566845694 CTITireStatus_33 521333;
BA_ "SigType" SG_ 2566845694 CTITireStatus_32 4;
BA_ "SPN" SG_ 2566845694 CTITireStatus_32 521332;
BA_ "SigType" SG_ 2566845694 CTITireStatus_31 4;
BA_ "SPN" SG_ 2566845694 CTITireStatus_31 521331;
BA_ "SigType" SG_ 2566845694 CTITireStatus_30 4;
BA_ "SPN" SG_ 2566845694 CTITireStatus_30 521330;
BA_ "SigType" SG_ 2566845694 CTITireStatus_23 4;
BA_ "SPN" SG_ 2566845694 CTITireStatus_23 521323;
BA_ "SigType" SG_ 2566845694 CTITireStatus_22 4;
BA_ "SPN" SG_ 2566845694 CTITireStatus_22 521322;
BA_ "SigType" SG_ 2566845694 CTITireStatus_21 4;
BA_ "SPN" SG_ 2566845694 CTITireStatus_21 521321;
BA_ "SigType" SG_ 2566845694 CTITireStatus_20 4;
BA_ "SPN" SG_ 2566845694 CTITireStatus_20 521320;
BA_ "SigType" SG_ 2566845694 CTITireStatus_13 4;
BA_ "SPN" SG_ 2566845694 CTITireStatus_13 521313;
BA_ "SigType" SG_ 2566845694 CTITireStatus_12 4;
BA_ "SPN" SG_ 2566845694 CTITireStatus_12 521312;
BA_ "SigType" SG_ 2566845694 CTITireStatus_11 4;
BA_ "SPN" SG_ 2566845694 CTITireStatus_11 521311;
BA_ "SigType" SG_ 2566845694 CTITireStatus_10 4;
BA_ "SPN" SG_ 2566845694 CTITireStatus_10 521310;
BA_ "SigType" SG_ 2566845694 CTITireStatus_01 4;
BA_ "SPN" SG_ 2566845694 CTITireStatus_01 521301;
BA_ "SigType" SG_ 2566845694 TireTemp_11 1;
BA_ "SPN" SG_ 2566845694 TireTemp_11 521111;
BA_ "TPMS_Space" SG_ 2566845694 TireTemp_11 10;
BA_ "SigType" SG_ 2566845694 TireTemp_33 1;
BA_ "SPN" SG_ 2566845694 TireTemp_33 521133;
BA_ "SigType" SG_ 2566845694 TireTemp_32 1;
BA_ "SPN" SG_ 2566845694 TireTemp_32 521132;
BA_ "SigType" SG_ 2566845694 TireTemp_31 1;
BA_ "SPN" SG_ 2566845694 TireTemp_31 521131;
BA_ "SigType" SG_ 2566845694 TireTemp_30 1;
BA_ "SPN" SG_ 2566845694 TireTemp_30 521130;
BA_ "SigType" SG_ 2566845694 TireTemp_23 1;
BA_ "SPN" SG_ 2566845694 TireTemp_23 521123;
BA_ "SigType" SG_ 2566845694 TireTemp_22 1;
BA_ "SPN" SG_ 2566845694 TireTemp_22 521122;
BA_ "SigType" SG_ 2566845694 TireTemp_21 1;
BA_ "SPN" SG_ 2566845694 TireTemp_21 521121;
BA_ "TPMS_Space" SG_ 2566845694 TireTemp_21 12;
BA_ "SigType" SG_ 2566845694 TireTemp_20 1;
BA_ "SPN" SG_ 2566845694 TireTemp_20 521120;
BA_ "TPMS_Space" SG_ 2566845694 TireTemp_20 11;
BA_ "SigType" SG_ 2566845694 TireTemp_13 1;
BA_ "SPN" SG_ 2566845694 TireTemp_13 521113;
BA_ "SigType" SG_ 2566845694 TireTemp_12 1;
BA_ "SPN" SG_ 2566845694 TireTemp_12 521112;
BA_ "SigType" SG_ 2566845694 TireTemp_10 1;
BA_ "SPN" SG_ 2566845694 TireTemp_10 521110;
BA_ "TPMS_Space" SG_ 2566845694 TireTemp_10 9;
BA_ "SigType" SG_ 2566845694 TireTemp_01 1;
BA_ "SPN" SG_ 2566845694 TireTemp_01 521101;
BA_ "TPMS_Space" SG_ 2566845694 TireTemp_01 8;
BA_ "SigType" SG_ 2566845694 TireTemp_00 1;
BA_ "SPN" SG_ 2566845694 TireTemp_00 521100;
BA_ "TPMS_Space" SG_ 2566845694 TireTemp_00 7;
BA_ "SPN" SG_ 2566845694 TirePressThresholdDetection_33 521633;
BA_ "SPN" SG_ 2566845694 TirePressThresholdDetection_32 521632;
BA_ "SPN" SG_ 2566845694 TirePressThresholdDetection_31 521631;
BA_ "SPN" SG_ 2566845694 TirePressThresholdDetection_30 521630;
BA_ "SPN" SG_ 2566845694 TirePressThresholdDetection_23 521623;
BA_ "SPN" SG_ 2566845694 TirePressThresholdDetection_22 521622;
BA_ "SPN" SG_ 2566845694 TirePressThresholdDetection_21 521621;
BA_ "SPN" SG_ 2566845694 TirePressThresholdDetection_20 521620;
BA_ "SPN" SG_ 2566845694 TirePressThresholdDetection_00 521600;
BA_ "SigType" SG_ 2566845694 TirePress_01 1;
BA_ "SPN" SG_ 2566845694 TirePress_01 521001;
BA_ "TPMS_Space" SG_ 2566845694 TirePress_01 2;
BA_ "SigType" SG_ 2566845694 TirePress_00 1;
BA_ "SPN" SG_ 2566845694 TirePress_00 521000;
BA_ "TPMS_Space" SG_ 2566845694 TirePress_00 1;
BA_ "SigType" SG_ 2566845694 CTIWheelSensorStatus_00 4;
BA_ "SPN" SG_ 2566845694 CTIWheelSensorStatus_00 521400;
BA_ "SigType" SG_ 2566845694 CTIWheelEndElectricalFault_00 4;
BA_ "SPN" SG_ 2566845694 CTIWheelEndElectricalFault_00 521200;
BA_ "SigType" SG_ 2566845694 CTITireStatus_00 4;
BA_ "SPN" SG_ 2566845694 CTITireStatus_00 521300;
BA_ "SigType" SG_ 2566845694 TireLocation 1;
BA_ "SPN" SG_ 2566845694 TireLocation 929;
BA_ "SAEDocument" SG_ 2566845694 TireLocation "J1939-71";
BA_ "SigType" SG_ 2566839038 NmbrOfSftwreIdentificationFields 1;
BA_ "SPN" SG_ 2566839038 NmbrOfSftwreIdentificationFields 965;
BA_ "SAEDocument" SG_ 2566839038 NmbrOfSftwreIdentificationFields "J1939-71";
BA_ "SigType" SG_ 2566839038 SoftwareIdentification 1;
BA_ "SPN" SG_ 2566839038 SoftwareIdentification 234;
BA_ "SAEDocument" SG_ 2566839038 SoftwareIdentification "J1939-71";
BA_ "SigType" SG_ 2566768126 ECUType 1;
BA_ "SPN" SG_ 2566768126 ECUType 2904;
BA_ "SAEDocument" SG_ 2566768126 ECUType "J1939-71";
BA_ "SigType" SG_ 2566768126 ECULocation 1;
BA_ "SPN" SG_ 2566768126 ECULocation 2903;
BA_ "SAEDocument" SG_ 2566768126 ECULocation "J1939-71";
BA_ "SigType" SG_ 2566768126 ECUSerialNumber 1;
BA_ "SPN" SG_ 2566768126 ECUSerialNumber 2902;
BA_ "SAEDocument" SG_ 2566768126 ECUSerialNumber "J1939-71";
BA_ "SigType" SG_ 2566768126 ECUPartNumber 1;
BA_ "SPN" SG_ 2566768126 ECUPartNumber 2901;
BA_ "SAEDocument" SG_ 2566768126 ECUPartNumber "J1939-71";
BA_ "SigType" SG_ 2566742270 FailureSpecificB1Counter 1;
BA_ "SPN" SG_ 2566742270 FailureSpecificB1Counter 4147;
BA_ "SAEDocument" SG_ 2566742270 FailureSpecificB1Counter "J1939_73";
BA_ "SPN" SG_ 2566742270 FailureModeIdentifier1 1215;
BA_ "SAEDocument" SG_ 2566742270 FailureModeIdentifier1 "J1939-73";
BA_ "SAEDocument" SG_ 2566742270 SPN1High "J1939-73";
BA_ "SPN" SG_ 2566742270 SPN1 1214;
BA_ "SAEDocument" SG_ 2566742270 SPN1 "J1939-73";
BA_ "SigType" SG_ 2566742526 SysGreatestB1Counter 1;
BA_ "SPN" SG_ 2566742526 SysGreatestB1Counter 4146;
BA_ "SAEDocument" SG_ 2566742526 SysGreatestB1Counter "J1939_73";
BA_ "SigType" SG_ 2566742526 SysCumulativeContinuousMITime 1;
BA_ "SPN" SG_ 2566742526 SysCumulativeContinuousMITime 4145;
BA_ "SAEDocument" SG_ 2566742526 SysCumulativeContinuousMITime "J1939_73";
BA_ "SigType" SG_ 2566742782 RegulationDescription 8;
BA_ "SPN" SG_ 2566742782 RegulationDescription 4144;
BA_ "SAEDocument" SG_ 2566742782 RegulationDescription "J1939_73";
BA_ "SigType" SG_ 2566743038 SysIncompleteMonitorCount 1;
BA_ "SPN" SG_ 2566743038 SysIncompleteMonitorCount 4143;
BA_ "SAEDocument" SG_ 2566743038 SysIncompleteMonitorCount "J1939_73";
BA_ "SPN" SG_ 2566743038 SysMalIndActivationMode 4142;
BA_ "SAEDocument" SG_ 2566743038 SysMalIndActivationMode "J1939_73";
BA_ "SigType" SG_ 2566743038 SysMalIndDisplayStrategy 4;
BA_ "SPN" SG_ 2566743038 SysMalIndDisplayStrategy 4141;
BA_ "SAEDocument" SG_ 2566743038 SysMalIndDisplayStrategy "J1939_73";
BA_ "SigType" SG_ 2566743038 SysContinuousMalfunctionInd 4;
BA_ "SPN" SG_ 2566743038 SysContinuousMalfunctionInd 4140;
BA_ "SAEDocument" SG_ 2566743038 SysContinuousMalfunctionInd "J1939_73";
BA_ "SigType" SG_ 2566743038 SysNonRoadworthyCompCount 1;
BA_ "SPN" SG_ 2566743038 SysNonRoadworthyCompCount 4139;
BA_ "SAEDocument" SG_ 2566743038 SysNonRoadworthyCompCount "J1939_73";
BA_ "SigType" SG_ 2566743294 VehicleCurrentMIAccumTime 1;
BA_ "SPN" SG_ 2566743294 VehicleCurrentMIAccumTime 4138;
BA_ "SAEDocument" SG_ 2566743294 VehicleCurrentMIAccumTime "J1939_73";
BA_ "SigType" SG_ 2566743294 VehicleIncompleteMonitorCount 1;
BA_ "SPN" SG_ 2566743294 VehicleIncompleteMonitorCount 4137;
BA_ "SAEDocument" SG_ 2566743294 VehicleIncompleteMonitorCount "J1939_73";
BA_ "SigType" SG_ 2566743294 VehicleMalfunctionIndActMode 4;
BA_ "SPN" SG_ 2566743294 VehicleMalfunctionIndActMode 4136;
BA_ "SAEDocument" SG_ 2566743294 VehicleMalfunctionIndActMode "J1939_73";
BA_ "SigType" SG_ 2566743294 VehicleMalfunctionIndStrategy 4;
BA_ "SPN" SG_ 2566743294 VehicleMalfunctionIndStrategy 4135;
BA_ "SAEDocument" SG_ 2566743294 VehicleMalfunctionIndStrategy "J1939_73";
BA_ "SigType" SG_ 2566743294 VehicleContinuousMalfunctionInd 4;
BA_ "SPN" SG_ 2566743294 VehicleContinuousMalfunctionInd 4134;
BA_ "SAEDocument" SG_ 2566743294 VehicleContinuousMalfunctionInd "J1939_73";
BA_ "SigType" SG_ 2566743294 VehicleNonRoadworthyCompCount 1;
BA_ "SPN" SG_ 2566743294 VehicleNonRoadworthyCompCount 4133;
BA_ "SAEDocument" SG_ 2566743294 VehicleNonRoadworthyCompCount "J1939_73";
BA_ "SigType" SG_ 2560687870 PMNTEDeficiencyAreaStatus 4;
BA_ "SPN" SG_ 2560687870 PMNTEDeficiencyAreaStatus 4132;
BA_ "SAEDocument" SG_ 2560687870 PMNTEDeficiencyAreaStatus "J1939_73";
BA_ "SigType" SG_ 2560687870 MnfcPMNTECarveOutAreaStatus 4;
BA_ "SPN" SG_ 2560687870 MnfcPMNTECarveOutAreaStatus 4131;
BA_ "SAEDocument" SG_ 2560687870 MnfcPMNTECarveOutAreaStatus "J1939_73";
BA_ "SigType" SG_ 2560687870 PMNTEControlAreaStatus 4;
BA_ "SPN" SG_ 2560687870 PMNTEControlAreaStatus 4130;
BA_ "SAEDocument" SG_ 2560687870 PMNTEControlAreaStatus "J1939_73";
BA_ "SigType" SG_ 2560687870 NOxNTEDeficiencyAreaStatus 4;
BA_ "SPN" SG_ 2560687870 NOxNTEDeficiencyAreaStatus 4129;
BA_ "SAEDocument" SG_ 2560687870 NOxNTEDeficiencyAreaStatus "J1939_73";
BA_ "SigType" SG_ 2560687870 MnfcNOxNTECarveOutAreaStatus 4;
BA_ "SPN" SG_ 2560687870 MnfcNOxNTECarveOutAreaStatus 4128;
BA_ "SAEDocument" SG_ 2560687870 MnfcNOxNTECarveOutAreaStatus "J1939_73";
BA_ "SigType" SG_ 2560687870 NOxNTEControlAreaStatus 4;
BA_ "SPN" SG_ 2560687870 NOxNTEControlAreaStatus 4127;
BA_ "SAEDocument" SG_ 2560687870 NOxNTEControlAreaStatus "J1939_73";
BA_ "SigType" SG_ 2292317950 AECDEngineHours1Timer2 1;
BA_ "SPN" SG_ 2292317950 AECDEngineHours1Timer2 4126;
BA_ "SAEDocument" SG_ 2292317950 AECDEngineHours1Timer2 "J1939_73";
BA_ "SigType" SG_ 2292317950 AECDEngineHours1Timer1 1;
BA_ "SPN" SG_ 2292317950 AECDEngineHours1Timer1 4125;
BA_ "SAEDocument" SG_ 2292317950 AECDEngineHours1Timer1 "J1939_73";
BA_ "SigType" SG_ 2292317950 AECDNumber1 1;
BA_ "SPN" SG_ 2292317950 AECDNumber1 4124;
BA_ "SAEDocument" SG_ 2292317950 AECDNumber1 "J1939_73";
BA_ "SigType" SG_ 2560884478 DTCWarnLampSupportStatus 4;
BA_ "SPN" SG_ 2560884478 DTCWarnLampSupportStatus 4115;
BA_ "SAEDocument" SG_ 2560884478 DTCWarnLampSupportStatus "J1939_73";
BA_ "SigType" SG_ 2560884478 DTCWarnLampSupportFlash 4;
BA_ "SPN" SG_ 2560884478 DTCWarnLampSupportFlash 4119;
BA_ "SAEDocument" SG_ 2560884478 DTCWarnLampSupportFlash "J1939_73";
BA_ "SigType" SG_ 2560884478 DTCStopLampSupportStatus 4;
BA_ "SPN" SG_ 2560884478 DTCStopLampSupportStatus 4114;
BA_ "SAEDocument" SG_ 2560884478 DTCStopLampSupportStatus "J1939_73";
BA_ "SigType" SG_ 2560884478 DTCStopLampSupportFlash 4;
BA_ "SPN" SG_ 2560884478 DTCStopLampSupportFlash 4118;
BA_ "SAEDocument" SG_ 2560884478 DTCStopLampSupportFlash "J1939_73";
BA_ "SigType" SG_ 2560884478 DTCProtectLampSupportStatus 4;
BA_ "SPN" SG_ 2560884478 DTCProtectLampSupportStatus 4116;
BA_ "SAEDocument" SG_ 2560884478 DTCProtectLampSupportStatus "J1939_73";
BA_ "SigType" SG_ 2560884478 DTCProtectLampSupportFlash 4;
BA_ "SPN" SG_ 2560884478 DTCProtectLampSupportFlash 4120;
BA_ "SAEDocument" SG_ 2560884478 DTCProtectLampSupportFlash "J1939_73";
BA_ "SPN" SG_ 2560884478 DTCMilSupportStatus 4113;
BA_ "SAEDocument" SG_ 2560884478 DTCMilSupportStatus "J1939_73";
BA_ "SPN" SG_ 2560884478 DTCMilSupportFlash 4117;
BA_ "SAEDocument" SG_ 2560884478 DTCMilSupportFlash "J1939_73";
BA_ "SigType" SG_ 2560884478 DTC1 7;
BA_ "SAEDocument" SG_ 2560884478 DTC1 "J1939-73";
BA_ "SigType" SG_ 2560950014 TestLimitMinimum 1;
BA_ "SPN" SG_ 2560950014 TestLimitMinimum 4112;
BA_ "SAEDocument" SG_ 2560950014 TestLimitMinimum "J1939_73";
BA_ "SigType" SG_ 2560950014 TestLimitMaximum 1;
BA_ "SPN" SG_ 2560950014 TestLimitMaximum 4111;
BA_ "SAEDocument" SG_ 2560950014 TestLimitMaximum "J1939_73";
BA_ "SigType" SG_ 2560950014 TestValue 1;
BA_ "SPN" SG_ 2560950014 TestValue 4110;
BA_ "SAEDocument" SG_ 2560950014 TestValue "J1939_73";
BA_ "SigType" SG_ 2560950014 SlotId 1;
BA_ "SPN" SG_ 2560950014 SlotId 4109;
BA_ "SAEDocument" SG_ 2560950014 SlotId "J1939_73";
BA_ "SAEDocument" SG_ 2560950014 TestIdentifier "J1939_73";
BA_ "SPN" SG_ 2560950014 FailureModeIdentifier1 1215;
BA_ "SAEDocument" SG_ 2560950014 FailureModeIdentifier1 "J1939-73";
BA_ "SAEDocument" SG_ 2560950014 SPN1High "J1939-73";
BA_ "SPN" SG_ 2560950014 SPN1 1214;
BA_ "SAEDocument" SG_ 2560950014 SPN1 "J1939-73";
BA_ "SigType" SG_ 2566836478 TestLimitMinimum 1;
BA_ "SPN" SG_ 2566836478 TestLimitMinimum 1228;
BA_ "SAEDocument" SG_ 2566836478 TestLimitMinimum "J1939-73";
BA_ "SigType" SG_ 2566836478 TestLimitMaximum 1;
BA_ "SPN" SG_ 2566836478 TestLimitMaximum 1227;
BA_ "SAEDocument" SG_ 2566836478 TestLimitMaximum "J1939-73";
BA_ "SigType" SG_ 2566836478 TestValue 1;
BA_ "SPN" SG_ 2566836478 TestValue 1226;
BA_ "SAEDocument" SG_ 2566836478 TestValue "J1939-73";
BA_ "SigType" SG_ 2566836478 TestType 1;
BA_ "GenSigStartValue" SG_ 2566836478 TestType 1;
BA_ "SPN" SG_ 2566836478 TestType 1225;
BA_ "SAEDocument" SG_ 2566836478 TestType "J1939-73";
BA_ "SigType" SG_ 2566836478 TestIdentifier 1;
BA_ "GenSigStartValue" SG_ 2566836478 TestIdentifier 1;
BA_ "SPN" SG_ 2566836478 TestIdentifier 1224;
BA_ "SAEDocument" SG_ 2566836478 TestIdentifier "J1939-73";
BA_ "SAEDocument" SG_ 2565078782 SPN1High "J1939-73";
BA_ "SPN" SG_ 2565078782 SPN1 1214;
BA_ "SAEDocument" SG_ 2565078782 SPN1 "J1939-73";
BA_ "SigType" SG_ 2565078782 TestIdentifier 1;
BA_ "GenSigStartValue" SG_ 2565078782 TestIdentifier 1;
BA_ "SPN" SG_ 2565078782 TestIdentifier 1224;
BA_ "SAEDocument" SG_ 2565078782 TestIdentifier "J1939-73";
BA_ "SPN" SG_ 2565078782 FailureModeIdentifier1 1215;
BA_ "SAEDocument" SG_ 2565078782 FailureModeIdentifier1 "J1939-73";
BA_ "SigType" SG_ 2566836222 FlashRedStopLamp 4;
BA_ "SPN" SG_ 2566836222 FlashRedStopLamp 3039;
BA_ "SAEDocument" SG_ 2566836222 FlashRedStopLamp "J1939-73";
BA_ "SigType" SG_ 2566836222 FlashProtectLamp 4;
BA_ "SPN" SG_ 2566836222 FlashProtectLamp 3041;
BA_ "SAEDocument" SG_ 2566836222 FlashProtectLamp "J1939-73";
BA_ "SigType" SG_ 2566836222 FlashMalfuncIndicatorLamp 4;
BA_ "SPN" SG_ 2566836222 FlashMalfuncIndicatorLamp 3038;
BA_ "SAEDocument" SG_ 2566836222 FlashMalfuncIndicatorLamp "J1939-73";
BA_ "SigType" SG_ 2566836222 FlashAmberWarningLamp 4;
BA_ "SPN" SG_ 2566836222 FlashAmberWarningLamp 3040;
BA_ "SAEDocument" SG_ 2566836222 FlashAmberWarningLamp "J1939-73";
BA_ "SigType" SG_ 2566836222 MalfunctionIndicatorLampStatus 4;
BA_ "SPN" SG_ 2566836222 MalfunctionIndicatorLampStatus 1213;
BA_ "SAEDocument" SG_ 2566836222 MalfunctionIndicatorLampStatus "J1939-73";
BA_ "SigType" SG_ 2566836222 RedStopLampState 4;
BA_ "SPN" SG_ 2566836222 RedStopLampState 623;
BA_ "SAEDocument" SG_ 2566836222 RedStopLampState "J1939-73";
BA_ "SigType" SG_ 2566836222 AmberWarningLampStatus 4;
BA_ "SPN" SG_ 2566836222 AmberWarningLampStatus 624;
BA_ "SAEDocument" SG_ 2566836222 AmberWarningLampStatus "J1939-73";
BA_ "SigType" SG_ 2566836222 ProtectLampStatus 4;
BA_ "SPN" SG_ 2566836222 ProtectLampStatus 987;
BA_ "SAEDocument" SG_ 2566836222 ProtectLampStatus "J1939-73";
BA_ "SigType" SG_ 2566836222 DTC5 7;
BA_ "SAEDocument" SG_ 2566836222 DTC5 "J1939-73";
BA_ "SigType" SG_ 2566836222 DTC4 7;
BA_ "SAEDocument" SG_ 2566836222 DTC4 "J1939-73";
BA_ "SigType" SG_ 2566836222 DTC3 7;
BA_ "SAEDocument" SG_ 2566836222 DTC3 "J1939-73";
BA_ "SigType" SG_ 2566836222 DTC2 7;
BA_ "SAEDocument" SG_ 2566836222 DTC2 "J1939-73";
BA_ "SigType" SG_ 2566836222 DTC1 7;
BA_ "SAEDocument" SG_ 2566836222 DTC1 "J1939-73";
BA_ "SystemSignalLongSymbol" SG_ 2566835966 NOxConvertingCatalystAdsorberSta "NOxConvertingCatalystAdsorberStatus";
BA_ "SystemSignalLongSymbol" SG_ 2566835966 BoostPressureControlSystemSuppor "BoostPressureControlSystemSupport";
BA_ "SystemSignalLongSymbol" SG_ 2566835966 NOxConvertingCatalystAdsorberSup "NOxConvertingCatalystAdsorberSupport";
BA_ "SAEDocument" SG_ 2566835966 MisfireMonitoringSupport "J1939-73";
BA_ "SigType" SG_ 2566835966 OBDCompliance 1;
BA_ "SPN" SG_ 2566835966 OBDCompliance 1220;
BA_ "SAEDocument" SG_ 2566835966 OBDCompliance "J1939-73";
BA_ "SigType" SG_ 2566835966 PreviouslyActiveTroubleCodes 1;
BA_ "SPN" SG_ 2566835966 PreviouslyActiveTroubleCodes 1219;
BA_ "SAEDocument" SG_ 2566835966 PreviouslyActiveTroubleCodes "J1939-73";
BA_ "SigType" SG_ 2566835966 ActiveTroubleCodes 1;
BA_ "SPN" SG_ 2566835966 ActiveTroubleCodes 1218;
BA_ "SAEDocument" SG_ 2566835966 ActiveTroubleCodes "J1939-73";
BA_ "SAEDocument" SG_ 2566835966 SecondAirSystemMonStatus "J1939-73";
BA_ "SAEDocument" SG_ 2566835966 EvaporativeSystemMonStatus "J1939-73";
BA_ "SAEDocument" SG_ 2566835966 ACSystemRefrigerantMonStatus "J1939-73";
BA_ "SAEDocument" SG_ 2566835966 OxygenSensorHeaterMonStatus "J1939-73";
BA_ "SAEDocument" SG_ 2566835966 OxygenSensorMonStatus "J1939-73";
BA_ "SAEDocument" SG_ 2566835966 EGRSystemMonitoringStatus "J1939-73";
BA_ "SAEDocument" SG_ 2566835966 CatalystMonStatus "J1939-73";
BA_ "SAEDocument" SG_ 2566835966 ColdStartAidSystemMonStatus "J1939-73";
BA_ "SAEDocument" SG_ 2566835966 HeatedCatalystMonStatus "J1939-73";
BA_ "SAEDocument" SG_ 2566835966 CatalystMonSupp "J1939-73";
BA_ "SAEDocument" SG_ 2566835966 ColdStartAidSystemMonSupp "J1939-73";
BA_ "SAEDocument" SG_ 2566835966 HeatedCatalystMonSupp "J1939-73";
BA_ "SAEDocument" SG_ 2566835966 EvaporativeSystemMonSupp "J1939-73";
BA_ "SAEDocument" SG_ 2566835966 SecondAirSystemMonSupp "J1939-73";
BA_ "SAEDocument" SG_ 2566835966 ACSystemRefrigerantMonSupp "J1939-73";
BA_ "SAEDocument" SG_ 2566835966 OxygenSensorMonSupp "J1939-73";
BA_ "SAEDocument" SG_ 2566835966 OxygenSensorHeaterMonSupp "J1939-73";
BA_ "SAEDocument" SG_ 2566835966 EGRSystemMonitoringSupp "J1939-73";
BA_ "SAEDocument" SG_ 2566835966 MisfireMonitoringStatus "J1939-73";
BA_ "SAEDocument" SG_ 2566835966 ComprehensiveCompMonStatus "J1939-73";
BA_ "SAEDocument" SG_ 2566835966 FuelSystemMonitoringStatus "J1939-73";
BA_ "SAEDocument" SG_ 2566835966 ComprehensiveComponentMonSupp "J1939-73";
BA_ "SAEDocument" SG_ 2566835966 FuelSystemMonitoringSupport "J1939-73";
BA_ "SigType" SG_ 2566835710 EngIntakeManifold1Press 1;
BA_ "SPN" SG_ 2566835710 EngIntakeManifold1Press 102;
BA_ "SAEDocument" SG_ 2566835710 EngIntakeManifold1Press "J1939-71";
BA_ "SPN" SG_ 2566835710 FreezeFrameLength 1217;
BA_ "SAEDocument" SG_ 2566835710 FreezeFrameLength "J1939-73";
BA_ "SigType" SG_ 2566835710 EngSpeed 1;
BA_ "SPN" SG_ 2566835710 EngSpeed 190;
BA_ "SAEDocument" SG_ 2566835710 EngSpeed "J1939-71";
BA_ "SPN" SG_ 2566835710 EngTorqueMode 899;
BA_ "SAEDocument" SG_ 2566835710 EngTorqueMode "J1939-71";
BA_ "SigType" SG_ 2566835710 WheelBasedVehicleSpeed 1;
BA_ "SPN" SG_ 2566835710 WheelBasedVehicleSpeed 84;
BA_ "SAEDocument" SG_ 2566835710 WheelBasedVehicleSpeed "J1939-71";
BA_ "SPN" SG_ 2566835710 EngPercentLoadAtCurrentSpeed 92;
BA_ "SAEDocument" SG_ 2566835710 EngPercentLoadAtCurrentSpeed "J1939-71";
BA_ "SigType" SG_ 2566835710 EngCoolantTemp 1;
BA_ "SPN" SG_ 2566835710 EngCoolantTemp 110;
BA_ "SAEDocument" SG_ 2566835710 EngCoolantTemp "J1939-71";
BA_ "SigType" SG_ 2566835710 DTC1 7;
BA_ "SAEDocument" SG_ 2566835710 DTC1 "J1939-73";
BA_ "SPN" SG_ 2566764542 ExpandedFreezeFrameLength 3149;
BA_ "SAEDocument" SG_ 2566764542 ExpandedFreezeFrameLength "J1939-73";
BA_ "SigType" SG_ 2566764542 DTC1 7;
BA_ "SAEDocument" SG_ 2566764542 DTC1 "J1939-73";
BA_ "SAEDocument" SG_ 2566764286 SPNSupported1High "J1939-73";
BA_ "SAEDocument" SG_ 2566764286 SPNSupportTypeSTR3 "J1939-73";
BA_ "SAEDocument" SG_ 2566764286 SPNSupportTypeSTR2 "J1939-73";
BA_ "SAEDocument" SG_ 2566764286 SPNSupportTypeEFF3 "J1939-73";
BA_ "SAEDocument" SG_ 2566764286 SPNSupportTypeEFF2 "J1939-73";
BA_ "SAEDocument" SG_ 2566764286 SPNSupportTypeDS3 "J1939-73";
BA_ "SAEDocument" SG_ 2566764286 SPNSupportTypeDS2 "J1939-73";
BA_ "SAEDocument" SG_ 2566764286 SPNSupported3High "J1939-73";
BA_ "SAEDocument" SG_ 2566764286 SPNSupported2High "J1939-73";
BA_ "SAEDocument" SG_ 2566764286 SPNSupported3 "J1939-73";
BA_ "SAEDocument" SG_ 2566764286 SPNSupported2 "J1939-73";
BA_ "SAEDocument" SG_ 2566764286 SPNDataLength3 "J1939-73";
BA_ "SAEDocument" SG_ 2566764286 SPNSupportTypeSTR1 "J1939-73";
BA_ "SAEDocument" SG_ 2566764286 SPNSupportTypeDS1 "J1939-73";
BA_ "SAEDocument" SG_ 2566764286 SPNSupportTypeEFF1 "J1939-73";
BA_ "SAEDocument" SG_ 2566764286 SPNDataLength2 "J1939-73";
BA_ "SPN" SG_ 2566764286 SPNDataLength1 4103;
BA_ "SAEDocument" SG_ 2566764286 SPNDataLength1 "J1939-73";
BA_ "SPN" SG_ 2566764286 SPNSupported1 3297;
BA_ "SAEDocument" SG_ 2566764286 SPNSupported1 "J1939-73";
BA_ "SigType" SG_ 2566764030 FlashRedStopLamp 4;
BA_ "SPN" SG_ 2566764030 FlashRedStopLamp 3039;
BA_ "SAEDocument" SG_ 2566764030 FlashRedStopLamp "J1939-73";
BA_ "SigType" SG_ 2566764030 FlashProtectLamp 4;
BA_ "SPN" SG_ 2566764030 FlashProtectLamp 3041;
BA_ "SAEDocument" SG_ 2566764030 FlashProtectLamp "J1939-73";
BA_ "SigType" SG_ 2566764030 FlashMalfuncIndicatorLamp 4;
BA_ "SPN" SG_ 2566764030 FlashMalfuncIndicatorLamp 3038;
BA_ "SAEDocument" SG_ 2566764030 FlashMalfuncIndicatorLamp "J1939-73";
BA_ "SigType" SG_ 2566764030 FlashAmberWarningLamp 4;
BA_ "SPN" SG_ 2566764030 FlashAmberWarningLamp 3040;
BA_ "SAEDocument" SG_ 2566764030 FlashAmberWarningLamp "J1939-73";
BA_ "SigType" SG_ 2566764030 MalfunctionIndicatorLampStatus 4;
BA_ "SPN" SG_ 2566764030 MalfunctionIndicatorLampStatus 1213;
BA_ "SAEDocument" SG_ 2566764030 MalfunctionIndicatorLampStatus "J1939-73";
BA_ "SigType" SG_ 2566764030 RedStopLampState 4;
BA_ "SPN" SG_ 2566764030 RedStopLampState 623;
BA_ "SAEDocument" SG_ 2566764030 RedStopLampState "J1939-73";
BA_ "SigType" SG_ 2566764030 AmberWarningLampStatus 4;
BA_ "SPN" SG_ 2566764030 AmberWarningLampStatus 624;
BA_ "SAEDocument" SG_ 2566764030 AmberWarningLampStatus "J1939-73";
BA_ "SigType" SG_ 2566764030 ProtectLampStatus 4;
BA_ "SPN" SG_ 2566764030 ProtectLampStatus 987;
BA_ "SAEDocument" SG_ 2566764030 ProtectLampStatus "J1939-73";
BA_ "SigType" SG_ 2566764030 DTC5 7;
BA_ "SAEDocument" SG_ 2566764030 DTC5 "J1939-73";
BA_ "SigType" SG_ 2566764030 DTC4 7;
BA_ "SAEDocument" SG_ 2566764030 DTC4 "J1939-73";
BA_ "SigType" SG_ 2566764030 DTC3 7;
BA_ "SAEDocument" SG_ 2566764030 DTC3 "J1939-73";
BA_ "SigType" SG_ 2566764030 DTC2 7;
BA_ "SAEDocument" SG_ 2566764030 DTC2 "J1939-73";
BA_ "SigType" SG_ 2566764030 DTC1 7;
BA_ "SAEDocument" SG_ 2566764030 DTC1 "J1939-73";
BA_ "SPN" SG_ 2562981630 IndividualDTCClearControlByte 3034;
BA_ "SAEDocument" SG_ 2562981630 IndividualDTCClearControlByte "J1939-73";
BA_ "SPN" SG_ 2562981630 CtrlByteIndicIndividualDTCClear 3035;
BA_ "SAEDocument" SG_ 2562981630 CtrlByteIndicIndividualDTCClear "J1939-73";
BA_ "SPN" SG_ 2562981630 SPN1 1214;
BA_ "SAEDocument" SG_ 2562981630 SPN1 "J1939-73";
BA_ "SAEDocument" SG_ 2562981630 SPN1High "J1939-73";
BA_ "SPN" SG_ 2562981630 FailureModeIdentifier1 1215;
BA_ "SAEDocument" SG_ 2562981630 FailureModeIdentifier1 "J1939-73";
BA_ "SigType" SG_ 2562850558 TimeSinceDTCsCleared 1;
BA_ "SPN" SG_ 2562850558 TimeSinceDTCsCleared 3296;
BA_ "SAEDocument" SG_ 2562850558 TimeSinceDTCsCleared "J1939-73";
BA_ "SigType" SG_ 2562850558 MinutesRunByEngineMILActivated 1;
BA_ "SPN" SG_ 2562850558 MinutesRunByEngineMILActivated 3295;
BA_ "SAEDocument" SG_ 2562850558 MinutesRunByEngineMILActivated "J1939-73";
BA_ "SigType" SG_ 2562850558 DistanceSinceDTCsCleared 1;
BA_ "SPN" SG_ 2562850558 DistanceSinceDTCsCleared 3294;
BA_ "SAEDocument" SG_ 2562850558 DistanceSinceDTCsCleared "J1939-73";
BA_ "SigType" SG_ 2562850558 DistanceWhileMILisActivated 1;
BA_ "SPN" SG_ 2562850558 DistanceWhileMILisActivated 3069;
BA_ "SAEDocument" SG_ 2562850558 DistanceWhileMILisActivated "J1939-73";
BA_ "SigType" SG_ 2562916094 ApplSysMonitorDenominator 1;
BA_ "SPN" SG_ 2562916094 ApplSysMonitorDenominator 3068;
BA_ "SAEDocument" SG_ 2562916094 ApplSysMonitorDenominator "J1939-73";
BA_ "SigType" SG_ 2562916094 ApplSysMonitorNumerator 1;
BA_ "SPN" SG_ 2562916094 ApplSysMonitorNumerator 3067;
BA_ "SAEDocument" SG_ 2562916094 ApplSysMonitorNumerator "J1939-73";
BA_ "SigType" SG_ 2562916094 SPNofApplSysMonitor 1;
BA_ "SPN" SG_ 2562916094 SPNofApplSysMonitor 3066;
BA_ "SAEDocument" SG_ 2562916094 SPNofApplSysMonitor "J1939-73";
BA_ "SigType" SG_ 2562916094 OBDMonitoringCondEncountered 1;
BA_ "SPN" SG_ 2562916094 OBDMonitoringCondEncountered 3049;
BA_ "SAEDocument" SG_ 2562916094 OBDMonitoringCondEncountered "J1939-73";
BA_ "SigType" SG_ 2562916094 IgnitionCycleCounter 1;
BA_ "SPN" SG_ 2562916094 IgnitionCycleCounter 3048;
BA_ "SAEDocument" SG_ 2562916094 IgnitionCycleCounter "J1939-73";
VAL_ 3221225472 TirePressThresholdDetection 7 "Not available" 6 "Error indicator" 5 "Not defined" 4 "Extreme under pressure  The tire pressure is at a level where the safety of the vehicle may be jeopardised" 3 "Under pressure  The tire pressure is lower than the pressure defined by the vehicle or tire manufacturer" 2 "No warning pressure  The tire pressure is within the thresholds defined by the vehicle or tire manufacturer" 1 "Over pressure  The tire pressure is higher than the pressure defined by the vehicle or tire manufacturer" 0 "Extreme over pressure  The tire pressure is at a level where the safety of the vehicle may be jeopardised" ;
VAL_ 3221225472 CTIWheelEndElectricalFault 3 "Not Supported" 2 "Error" 1 "Not Defined" 0 "Ok  No Fault" ;
VAL_ 3221225472 CTITireStatus 3 "Not Supported" 2 "Error" 1 "Tire leak detected" 0 "Ok no fault" ;
VAL_ 3221225472 CTIWheelSensorStatus 3 "Not Supported" 2 "Not Defined" 1 "On tire is polled" 0 "Off / isolated from CTI Pressure Controller" ;
VAL_ 3221225472 EngTurningGearEngaged 1 "Engaged" 0 "Not engaged" 3 "Not available" 2 "Error" ;
VAL_ 2632777470 PGNumber 255 "NotAvailable" ;
VAL_ 2632777470 ControlByte 24 "EAbort" 23 "EEoMACK" 22 "EDPO" 21 "ECTS" 20 "ERTS" 255 "Abort" 32 "BAM" 19 "EoMA" 17 "CTS" 16 "RTS" ;
VAL_ 2561605374 TireLocation 51 "Axle3_Position3" 50 "Axle3_Position2" 49 "Axle3_Position1" 35 "Axle2_Position3" 34 "Axle2_Position2" 33 "Axle2_Position1" 19 "Axle1_Position3" 18 "Axle1_Position2" 17 "Axle1_Position1" 1 "Axle0_Position1" 48 "Axle3_Position0" 32 "Axle2_Position0" 16 "Axle1_Position0" 0 "Axle0_Position0" ;
VAL_ 2560818942 FailureModeIdentifier1 31 "Not available" 19 "Received network data in error" 18 "Below normal (moderately severe)" 17 "Below normal (least severe)" 16 "Above normal (moderately severe)" 15 "Above normal (least severe)" 14 "Special intstructions" 13 "Out of calibration" 12 "Bad intelligent device" 11 "Root cause not known" 10 "Abnormal rate of change" 9 "Abnormal update rate" 8 "Abnormal frequency" 7 "Mechanical system not responding" 6 "Current above normal" 5 "Current below normal" 4 "Voltage below normal" 3 "Voltage above normal" 2 "Data erratic" 1 "Below normal (most severe)" 0 "Above normal (most severe)" ;
VAL_ 2566764798 MisfireMonitoringComplete 1 "EnabledForCycle" 0 "DisabledForRestOfCycle" ;
VAL_ 2566764798 MisfireMonitoringEnabled 1 "EnabledForCycle" 0 "DisabledForRestOfCycle" ;
VAL_ 2566764798 FuelSystemMonitoringEnabled 1 "NotCompleteCycle" 0 "CompleteCycleOrNotSupported" ;
VAL_ 2566764798 ComprehensiveComptMonComplete 1 "NotCompleteCycle" 0 "CompleteCycleOrNotSupported" ;
VAL_ 2566764798 ComprehensiveCompMonEnabled 1 "NotCompleteCycle" 0 "CompleteCycleOrNotSupported" ;
VAL_ 2566764798 SecondAirSystemMonComplete 1 "EnabledForCycle" 0 "DisabledForRestOfCycle" ;
VAL_ 2566764798 SecondAirSystemMonEnabled 1 "EnabledForCycle" 0 "DisabledForRestOfCycle" ;
VAL_ 2566764798 OxygenSensorMonComplete 1 "EnabledForCycle" 0 "DisabledForRestOfCycle" ;
VAL_ 2566764798 OxygenSensorMonEnabled 1 "NotCompleteCycle" 0 "CompleteCycleOrNotSupported" ;
VAL_ 2566764798 OxygenSensorHeaterMonComplete 1 "EnabledForCycle" 0 "DisabledForRestOfCycle" ;
VAL_ 2566764798 OxygenSensorHeaterMonEnabled 1 "NotCompleteCycle" 0 "CompleteCycleOrNotSupported" ;
VAL_ 2566764798 HeatedCatalystMonComplete 1 "EnabledForCycle" 0 "DisabledForRestOfCycle" ;
VAL_ 2566764798 HeatedCatalystMonEnabled 1 "EnabledForCycle" 0 "DisabledForRestOfCycle" ;
VAL_ 2566764798 EvaporativeSystemMonComplete 1 "NotCompleteCycle" 0 "CompleteCycleOrNotSupported" ;
VAL_ 2566764798 EvaporativeSystemMonEnabled 1 "NotCompleteCycle" 0 "CompleteCycleOrNotSupported" ;
VAL_ 2566764798 EGRSystemMonitoringComplete 1 "NotCompleteCycle" 0 "CompleteCycleOrNotSupported" ;
VAL_ 2566764798 EGRSystemMonitoringEnabled 1 "EnabledForCycle" 0 "DisabledForRestOfCycle" ;
VAL_ 2566764798 ColdStartAidSystemMonComplete 1 "EnabledForCycle" 0 "DisabledForRestOfCycle" ;
VAL_ 2566764798 ColdStartAidSystemMonEnabled 1 "EnabledForCycle" 0 "DisabledForRestOfCycle" ;
VAL_ 2566764798 CatalystMonComplete 1 "NotCompleteCycle" 0 "CompleteCycleOrNotSupported" ;
VAL_ 2566764798 CatalystMonEnabled 1 "NotCompleteCycle" 0 "CompleteCycleOrNotSupported" ;
VAL_ 2566764798 ACSystemRefrigerantMonComplete 1 "NotCompleteCycle" 0 "CompleteCycleOrNotSupported" ;
VAL_ 2566764798 ACSystemRefrigerantMonEnabled 1 "NotCompleteCycle" 0 "CompleteCycleOrNotSupported" ;
VAL_ 2566764798 FuelSystemMonitoringComplete 1 "NotCompleteCycle" 0 "CompleteCycleOrNotSupported" ;
VAL_ 2564095742 SecurityEntityType 3 "Data is Certificate" 2 "Data is Session Key" 1 "Data is Long Key" 0 "Data is Long Seed" ;
VAL_ 2566765054 TireLocation 51 "Axle3_Position3" 50 "Axle3_Position2" 49 "Axle3_Position1" 35 "Axle2_Position3" 34 "Axle2_Position2" 33 "Axle2_Position1" 19 "Axle1_Position3" 18 "Axle1_Position2" 17 "Axle1_Position1" 1 "Axle0_Position1" 48 "Axle3_Position0" 32 "Axle2_Position0" 16 "Axle1_Position0" 0 "Axle0_Position0" ;
VAL_ 2566845694 TirePressThresholdDetection_13 7 "NotAvailable" 6 "ErrorIndicator" 5 "NotDefined" 4 "ExtrmUndrPrssTrPrssrIsAtALvlWhr" 3 "UndrPrssTrPrssrIsLwrThnThPrssrD" 2 "NWrnngPrssTrPrssrIsWthnThThrshl" 1 "OvrPrssTrPrssrIsHghrThnThPrssrD" 0 "ExtrmOvrPrssTrPrssrIsAtALvlWhrT" ;
VAL_ 2566845694 TirePressThresholdDetection_12 7 "NotAvailable" 6 "ErrorIndicator" 5 "NotDefined" 4 "ExtrmUndrPrssTrPrssrIsAtALvlWhr" 3 "UndrPrssTrPrssrIsLwrThnThPrssrD" 2 "NWrnngPrssTrPrssrIsWthnThThrshl" 1 "OvrPrssTrPrssrIsHghrThnThPrssrD" 0 "ExtrmOvrPrssTrPrssrIsAtALvlWhrT" ;
VAL_ 2566845694 TirePressThresholdDetection_11 7 "NotAvailable" 6 "ErrorIndicator" 5 "NotDefined" 4 "ExtrmUndrPrssTrPrssrIsAtALvlWhr" 3 "UndrPrssTrPrssrIsLwrThnThPrssrD" 2 "NWrnngPrssTrPrssrIsWthnThThrshl" 1 "OvrPrssTrPrssrIsHghrThnThPrssrD" 0 "ExtrmOvrPrssTrPrssrIsAtALvlWhrT" ;
VAL_ 2566845694 TirePressThresholdDetection_10 7 "NotAvailable" 6 "ErrorIndicator" 5 "NotDefined" 4 "ExtrmUndrPrssTrPrssrIsAtALvlWhr" 3 "UndrPrssTrPrssrIsLwrThnThPrssrD" 2 "NWrnngPrssTrPrssrIsWthnThThrshl" 1 "OvrPrssTrPrssrIsHghrThnThPrssrD" 0 "ExtrmOvrPrssTrPrssrIsAtALvlWhrT" ;
VAL_ 2566845694 TirePressThresholdDetection_01 7 "NotAvailable" 6 "ErrorIndicator" 5 "NotDefined" 4 "ExtrmUndrPrssTrPrssrIsAtALvlWhr" 3 "UndrPrssTrPrssrIsLwrThnThPrssrD" 2 "NWrnngPrssTrPrssrIsWthnThThrshl" 1 "OvrPrssTrPrssrIsHghrThnThPrssrD" 0 "ExtrmOvrPrssTrPrssrIsAtALvlWhrT" ;
VAL_ 2566845694 CTIWheelSensorStatus_33 3 "NotSupported" 2 "NotDefined" 1 "On" 0 "Off_IsolatedFromCTIPressCtrl" ;
VAL_ 2566845694 CTIWheelSensorStatus_32 3 "NotSupported" 2 "NotDefined" 1 "On" 0 "Off_IsolatedFromCTIPressCtrl" ;
VAL_ 2566845694 CTIWheelSensorStatus_31 3 "NotSupported" 2 "NotDefined" 1 "On" 0 "Off_IsolatedFromCTIPressCtrl" ;
VAL_ 2566845694 CTIWheelSensorStatus_30 3 "NotSupported" 2 "NotDefined" 1 "On" 0 "Off_IsolatedFromCTIPressCtrl" ;
VAL_ 2566845694 CTIWheelSensorStatus_23 3 "NotSupported" 2 "NotDefined" 1 "On" 0 "Off_IsolatedFromCTIPressCtrl" ;
VAL_ 2566845694 CTIWheelSensorStatus_22 3 "NotSupported" 2 "NotDefined" 1 "On" 0 "Off_IsolatedFromCTIPressCtrl" ;
VAL_ 2566845694 CTIWheelSensorStatus_21 3 "NotSupported" 2 "NotDefined" 1 "On" 0 "Off_IsolatedFromCTIPressCtrl" ;
VAL_ 2566845694 CTIWheelSensorStatus_20 3 "NotSupported" 2 "NotDefined" 1 "On" 0 "Off_IsolatedFromCTIPressCtrl" ;
VAL_ 2566845694 CTIWheelSensorStatus_13 3 "NotSupported" 2 "NotDefined" 1 "On" 0 "Off_IsolatedFromCTIPressCtrl" ;
VAL_ 2566845694 CTIWheelSensorStatus_12 3 "NotSupported" 2 "NotDefined" 1 "On" 0 "Off_IsolatedFromCTIPressCtrl" ;
VAL_ 2566845694 CTIWheelSensorStatus_11 3 "NotSupported" 2 "NotDefined" 1 "On" 0 "Off_IsolatedFromCTIPressCtrl" ;
VAL_ 2566845694 CTIWheelSensorStatus_10 3 "NotSupported" 2 "NotDefined" 1 "On" 0 "Off_IsolatedFromCTIPressCtrl" ;
VAL_ 2566845694 CTIWheelSensorStatus_01 3 "NotSupported" 2 "NotDefined" 1 "On" 0 "Off_IsolatedFromCTIPressCtrl" ;
VAL_ 2566845694 CTIWheelEndElectricalFault_33 3 "NotSupported" 2 "Error" 1 "NotDefined" 0 "Ok" ;
VAL_ 2566845694 CTIWheelEndElectricalFault_32 3 "NotSupported" 2 "Error" 1 "NotDefined" 0 "Ok" ;
VAL_ 2566845694 CTIWheelEndElectricalFault_31 3 "NotSupported" 2 "Error" 1 "NotDefined" 0 "Ok" ;
VAL_ 2566845694 CTIWheelEndElectricalFault_30 3 "NotSupported" 2 "Error" 1 "NotDefined" 0 "Ok" ;
VAL_ 2566845694 CTIWheelEndElectricalFault_23 3 "NotSupported" 2 "Error" 1 "NotDefined" 0 "Ok" ;
VAL_ 2566845694 CTIWheelEndElectricalFault_22 3 "NotSupported" 2 "Error" 1 "NotDefined" 0 "Ok" ;
VAL_ 2566845694 CTIWheelEndElectricalFault_21 3 "NotSupported" 2 "Error" 1 "NotDefined" 0 "Ok" ;
VAL_ 2566845694 CTIWheelEndElectricalFault_20 3 "NotSupported" 2 "Error" 1 "NotDefined" 0 "Ok" ;
VAL_ 2566845694 CTIWheelEndElectricalFault_13 3 "NotSupported" 2 "Error" 1 "NotDefined" 0 "Ok" ;
VAL_ 2566845694 CTIWheelEndElectricalFault_12 3 "NotSupported" 2 "Error" 1 "NotDefined" 0 "Ok" ;
VAL_ 2566845694 CTIWheelEndElectricalFault_11 3 "NotSupported" 2 "Error" 1 "NotDefined" 0 "Ok" ;
VAL_ 2566845694 CTIWheelEndElectricalFault_10 3 "NotSupported" 2 "Error" 1 "NotDefined" 0 "Ok" ;
VAL_ 2566845694 CTIWheelEndElectricalFault_01 3 "NotSupported" 2 "Error" 1 "NotDefined" 0 "Ok" ;
VAL_ 2566845694 CTITireStatus_33 3 "NotSupported" 2 "Error" 1 "TireLeakDetected" 0 "Ok" ;
VAL_ 2566845694 CTITireStatus_32 3 "NotSupported" 2 "Error" 1 "TireLeakDetected" 0 "Ok" ;
VAL_ 2566845694 CTITireStatus_31 3 "NotSupported" 2 "Error" 1 "TireLeakDetected" 0 "Ok" ;
VAL_ 2566845694 CTITireStatus_30 3 "NotSupported" 2 "Error" 1 "TireLeakDetected" 0 "Ok" ;
VAL_ 2566845694 CTITireStatus_23 3 "NotSupported" 2 "Error" 1 "TireLeakDetected" 0 "Ok" ;
VAL_ 2566845694 CTITireStatus_22 3 "NotSupported" 2 "Error" 1 "TireLeakDetected" 0 "Ok" ;
VAL_ 2566845694 CTITireStatus_21 3 "NotSupported" 2 "Error" 1 "TireLeakDetected" 0 "Ok" ;
VAL_ 2566845694 CTITireStatus_20 3 "NotSupported" 2 "Error" 1 "TireLeakDetected" 0 "Ok" ;
VAL_ 2566845694 CTITireStatus_13 3 "NotSupported" 2 "Error" 1 "TireLeakDetected" 0 "Ok" ;
VAL_ 2566845694 CTITireStatus_12 3 "NotSupported" 2 "Error" 1 "TireLeakDetected" 0 "Ok" ;
VAL_ 2566845694 CTITireStatus_11 3 "NotSupported" 2 "Error" 1 "TireLeakDetected" 0 "Ok" ;
VAL_ 2566845694 CTITireStatus_10 3 "NotSupported" 2 "Error" 1 "TireLeakDetected" 0 "Ok" ;
VAL_ 2566845694 CTITireStatus_01 3 "NotSupported" 2 "Error" 1 "TireLeakDetected" 0 "Ok" ;
VAL_ 2566845694 TirePressThresholdDetection_33 7 "NotAvailable" 6 "ErrorIndicator" 5 "NotDefined" 4 "ExtrmUndrPrssTrPrssrIsAtALvlWhr" 3 "UndrPrssTrPrssrIsLwrThnThPrssrD" 2 "NWrnngPrssTrPrssrIsWthnThThrshl" 1 "OvrPrssTrPrssrIsHghrThnThPrssrD" 0 "ExtrmOvrPrssTrPrssrIsAtALvlWhrT" ;
VAL_ 2566845694 TirePressThresholdDetection_32 7 "NotAvailable" 6 "ErrorIndicator" 5 "NotDefined" 4 "ExtrmUndrPrssTrPrssrIsAtALvlWhr" 3 "UndrPrssTrPrssrIsLwrThnThPrssrD" 2 "NWrnngPrssTrPrssrIsWthnThThrshl" 1 "OvrPrssTrPrssrIsHghrThnThPrssrD" 0 "ExtrmOvrPrssTrPrssrIsAtALvlWhrT" ;
VAL_ 2566845694 TirePressThresholdDetection_31 7 "NotAvailable" 6 "ErrorIndicator" 5 "NotDefined" 4 "ExtrmUndrPrssTrPrssrIsAtALvlWhr" 3 "UndrPrssTrPrssrIsLwrThnThPrssrD" 2 "NWrnngPrssTrPrssrIsWthnThThrshl" 1 "OvrPrssTrPrssrIsHghrThnThPrssrD" 0 "ExtrmOvrPrssTrPrssrIsAtALvlWhrT" ;
VAL_ 2566845694 TirePressThresholdDetection_30 7 "NotAvailable" 6 "ErrorIndicator" 5 "NotDefined" 4 "ExtrmUndrPrssTrPrssrIsAtALvlWhr" 3 "UndrPrssTrPrssrIsLwrThnThPrssrD" 2 "NWrnngPrssTrPrssrIsWthnThThrshl" 1 "OvrPrssTrPrssrIsHghrThnThPrssrD" 0 "ExtrmOvrPrssTrPrssrIsAtALvlWhrT" ;
VAL_ 2566845694 TirePressThresholdDetection_23 7 "NotAvailable" 6 "ErrorIndicator" 5 "NotDefined" 4 "ExtrmUndrPrssTrPrssrIsAtALvlWhr" 3 "UndrPrssTrPrssrIsLwrThnThPrssrD" 2 "NWrnngPrssTrPrssrIsWthnThThrshl" 1 "OvrPrssTrPrssrIsHghrThnThPrssrD" 0 "ExtrmOvrPrssTrPrssrIsAtALvlWhrT" ;
VAL_ 2566845694 TirePressThresholdDetection_22 7 "NotAvailable" 6 "ErrorIndicator" 5 "NotDefined" 4 "ExtrmUndrPrssTrPrssrIsAtALvlWhr" 3 "UndrPrssTrPrssrIsLwrThnThPrssrD" 2 "NWrnngPrssTrPrssrIsWthnThThrshl" 1 "OvrPrssTrPrssrIsHghrThnThPrssrD" 0 "ExtrmOvrPrssTrPrssrIsAtALvlWhrT" ;
VAL_ 2566845694 TirePressThresholdDetection_21 7 "NotAvailable" 6 "ErrorIndicator" 5 "NotDefined" 4 "ExtrmUndrPrssTrPrssrIsAtALvlWhr" 3 "UndrPrssTrPrssrIsLwrThnThPrssrD" 2 "NWrnngPrssTrPrssrIsWthnThThrshl" 1 "OvrPrssTrPrssrIsHghrThnThPrssrD" 0 "ExtrmOvrPrssTrPrssrIsAtALvlWhrT" ;
VAL_ 2566845694 TirePressThresholdDetection_20 7 "NotAvailable" 6 "ErrorIndicator" 5 "NotDefined" 4 "ExtrmUndrPrssTrPrssrIsAtALvlWhr" 3 "UndrPrssTrPrssrIsLwrThnThPrssrD" 2 "NWrnngPrssTrPrssrIsWthnThThrshl" 1 "OvrPrssTrPrssrIsHghrThnThPrssrD" 0 "ExtrmOvrPrssTrPrssrIsAtALvlWhrT" ;
VAL_ 2566845694 TirePressThresholdDetection_00 7 "NotAvailable" 6 "ErrorIndicator" 5 "NotDefined" 4 "ExtrmUndrPrssTrPrssrIsAtALvlWhr" 3 "UndrPrssTrPrssrIsLwrThnThPrssrD" 2 "NWrnngPrssTrPrssrIsWthnThThrshl" 1 "OvrPrssTrPrssrIsHghrThnThPrssrD" 0 "ExtrmOvrPrssTrPrssrIsAtALvlWhrT" ;
VAL_ 2566845694 CTIWheelSensorStatus_00 3 "NotSupported" 2 "NotDefined" 1 "On" 0 "Off_IsolatedFromCTIPressCtrl" ;
VAL_ 2566845694 CTIWheelEndElectricalFault_00 3 "NotSupported" 2 "Error" 1 "NotDefined" 0 "Ok" ;
VAL_ 2566845694 CTITireStatus_00 3 "NotSupported" 2 "Error" 1 "TireLeakDetected" 0 "Ok" ;
VAL_ 2566742270 FailureModeIdentifier1 31 "Not available" 19 "Received network data in error" 18 "Below normal (moderately severe)" 17 "Below normal (least severe)" 16 "Above normal (moderately severe)" 15 "Above normal (least severe)" 14 "Special intstructions" 13 "Out of calibration" 12 "Bad intelligent device" 11 "Root cause not known" 10 "Abnormal rate of change" 9 "Abnormal update rate" 8 "Abnormal frequency" 7 "Mechanical system not responding" 6 "Current above normal" 5 "Current below normal" 4 "Voltage below normal" 3 "Voltage above normal" 2 "Data erratic" 1 "Below normal (most severe)" 0 "Above normal (most severe)" ;
VAL_ 2560687870 PMNTEDeficiencyAreaStatus 3 "NotAvailable" 2 "Reserved" 1 "InsideControlArea" 0 "OutsideControlArea" ;
VAL_ 2560687870 MnfcPMNTECarveOutAreaStatus 3 "NotAvailable" 2 "Reserved" 1 "InsideControlArea" 0 "OutsideControlArea" ;
VAL_ 2560687870 PMNTEControlAreaStatus 3 "NotAvailable" 2 "Reserved" 1 "InsideControlArea" 0 "OutsideControlArea" ;
VAL_ 2560687870 NOxNTEDeficiencyAreaStatus 3 "NotAvailable" 2 "Reserved" 1 "InsideControlArea" 0 "OutsideControlArea" ;
VAL_ 2560687870 MnfcNOxNTECarveOutAreaStatus 3 "NotAvailable" 2 "Reserved" 1 "InsideControlArea" 0 "OutsideControlArea" ;
VAL_ 2560687870 NOxNTEControlAreaStatus 3 "NotAvailable" 2 "Reserved" 1 "InsideControlArea" 0 "OutsideControlArea" ;
VAL_ 2560884478 DTCWarnLampSupportStatus 3 "Unavailable" 2 "Reserved" 1 "LampOn" 0 "LampOff" ;
VAL_ 2560884478 DTCWarnLampSupportFlash 3 "Unavailable" 2 "Reserved" 1 "FastFlash" 0 "SlowFlash" ;
VAL_ 2560884478 DTCStopLampSupportStatus 3 "Unavailable" 2 "Reserved" 1 "LampOn" 0 "LampOff" ;
VAL_ 2560884478 DTCStopLampSupportFlash 3 "Unavailable" 2 "Reserved" 1 "FastFlash" 0 "SlowFlash" ;
VAL_ 2560884478 DTCProtectLampSupportStatus 3 "Unavailable" 2 "Reserved" 1 "LampOn" 0 "LampOff" ;
VAL_ 2560884478 DTCProtectLampSupportFlash 3 "Unavailable" 2 "Reserved" 1 "FastFlash" 0 "SlowFlash" ;
VAL_ 2560884478 DTCMilSupportStatus 3 "Unavailable" 2 "ShortMI" 1 "LampOn" 0 "LampOff" ;
VAL_ 2560884478 DTCMilSupportFlash 3 "Unavailable" 2 "Class_C_DTC" 1 "FastFlash" 0 "SlowFlash" ;
VAL_ 2560950014 FailureModeIdentifier1 31 "Not available" 19 "Received network data in error" 18 "Below normal (moderately severe)" 17 "Below normal (least severe)" 16 "Above normal (moderately severe)" 15 "Above normal (least severe)" 14 "Special intstructions" 13 "Out of calibration" 12 "Bad intelligent device" 11 "Root cause not known" 10 "Abnormal rate of change" 9 "Abnormal update rate" 8 "Abnormal frequency" 7 "Mechanical system not responding" 6 "Current above normal" 5 "Current below normal" 4 "Voltage below normal" 3 "Voltage above normal" 2 "Data erratic" 1 "Below normal (most severe)" 0 "Above normal (most severe)" ;
VAL_ 2566836478 TestIdentifier 250 "Last Measured Scaled Results" 249 "Command Standard Test" 247 "All scaled test results" ;
VAL_ 2565078782 TestIdentifier 250 "Last Measured Scaled Results" 249 "Command Standard Test" 247 "All scaled test results" ;
VAL_ 2565078782 FailureModeIdentifier1 31 "Not available" 19 "Received network data in error" 18 "Below normal (moderately severe)" 17 "Below normal (least severe)" 16 "Above normal (moderately severe)" 15 "Above normal (least severe)" 14 "Special intstructions" 13 "Out of calibration" 12 "Bad intelligent device" 11 "Root cause not known" 10 "Abnormal rate of change" 9 "Abnormal update rate" 8 "Abnormal frequency" 7 "Mechanical system not responding" 6 "Current above normal" 5 "Current below normal" 4 "Voltage below normal" 3 "Voltage above normal" 2 "Data erratic" 1 "Below normal (most severe)" 0 "Above normal (most severe)" ;
VAL_ 2566836222 FlashRedStopLamp 3 "Unavailable / Do Not Flash" 2 "Reserved" 1 "Fast Flash" 0 "Slow Flash" ;
VAL_ 2566836222 FlashProtectLamp 3 "Unavailable / Do Not Flash" 2 "Reserved" 1 "Fast Flash" 0 "Slow Flash" ;
VAL_ 2566836222 FlashMalfuncIndicatorLamp 3 "Unavailable / Do Not Flash" 2 "Reserved" 1 "Fast Flash" 0 "Slow Flash" ;
VAL_ 2566836222 FlashAmberWarningLamp 3 "Unavailable / Do Not Flash" 2 "Reserved" 1 "Fast Flash" 0 "Slow Flash" ;
VAL_ 2566836222 MalfunctionIndicatorLampStatus 3 "Not available" 2 "Reserved" 1 "Lamp on" 0 "Lamp off" ;
VAL_ 2566836222 RedStopLampState 3 "Not available" 2 "Reserved" 1 "Lamp on" 0 "Lamp off" ;
VAL_ 2566836222 AmberWarningLampStatus 3 "Not available" 2 "Reserved" 1 "Lamp on" 0 "Lamp off" ;
VAL_ 2566836222 ProtectLampStatus 3 "Not available" 2 "Reserved" 1 "Lamp on" 0 "Lamp off" ;
VAL_ 2566835966 MisfireMonitoringSupport 3 "Not available" 2 "Reserved" 1 "test supported" 0 "test not supported" ;
VAL_ 2566835966 OBDCompliance 10 "JOBD" 11 "JOBD and OBD II" 12 "JOBD and EOBD" 13 "JOBD, EOBD and OBD II" 14 "Heavy Duty Vehicles (EURO IV) B1" 15 "Heavy Duty Vehicles (EURO V) B2" 16 "Heavy Duty Vehicles (EURO EEC) C" 17 "EMD" 18 "EMD+" 19 "HD OBD P" 20 "HD OBD" 21 "WWH OBD" 22 "OBD II (California, ARB 07/08)" 23 "HD EOBD" 25 "OBD-M (SI-SD/I)" 6 "EOBD" 7 "EOBD and OBD II" 8 "EOBD and OBD" 9 "EOBD, OBD and OBD II" 5 "Not intended to meet OBD II req." 4 "OBD I" 3 "OBD and OBD II" 2 "OBD (Federal, EPA)" 1 "OBD II (California, ARB)" 0 "Reserver for assignment by SAE" ;
VAL_ 2566835966 SecondAirSystemMonStatus 1 "TestNotComplete" 0 "TestComplete" ;
VAL_ 2566835966 EvaporativeSystemMonStatus 1 "TestNotComplete" 0 "TestComplete" ;
VAL_ 2566835966 ACSystemRefrigerantMonStatus 1 "TestNotComplete" 0 "TestComplete" ;
VAL_ 2566835966 OxygenSensorHeaterMonStatus 1 "TestNotComplete" 0 "TestComplete" ;
VAL_ 2566835966 OxygenSensorMonStatus 1 "test not complete" 0 "test complete" ;
VAL_ 2566835966 EGRSystemMonitoringStatus 1 "TestNotComplete" 0 "TestComplete" ;
VAL_ 2566835966 CatalystMonStatus 0 "TestComplete" 1 "TestNotComplete" ;
VAL_ 2566835966 ColdStartAidSystemMonStatus 1 "TestNotComplete" 0 "TestComplete" ;
VAL_ 2566835966 HeatedCatalystMonStatus 1 "TestNotComplete" 0 "TestComplete" ;
VAL_ 2566835966 CatalystMonSupp 1 "TestSupported" 0 "TestNotSupported" ;
VAL_ 2566835966 ColdStartAidSystemMonSupp 1 "TestSupported" 0 "TestNotSupported" ;
VAL_ 2566835966 HeatedCatalystMonSupp 1 "TestSupported" 0 "TestNotSupported" ;
VAL_ 2566835966 EvaporativeSystemMonSupp 1 "TestSupported" 0 "TestNotSupported" ;
VAL_ 2566835966 SecondAirSystemMonSupp 1 "TestSupported" 0 "TestNotSupported" ;
VAL_ 2566835966 ACSystemRefrigerantMonSupp 1 "TestSupported" 0 "TestNotSupported" ;
VAL_ 2566835966 OxygenSensorMonSupp 1 "TestSupported" 0 "TestNotSupported" ;
VAL_ 2566835966 OxygenSensorHeaterMonSupp 1 "TestSupported" 0 "TestNotSupported" ;
VAL_ 2566835966 EGRSystemMonitoringSupp 1 "TestSupported" 0 "TestNotSupported" ;
VAL_ 2566835966 MisfireMonitoringStatus 1 "test not complete" 0 "test complete" ;
VAL_ 2566835966 ComprehensiveCompMonStatus 1 "test not complete" 0 "test complete" ;
VAL_ 2566835966 FuelSystemMonitoringStatus 1 "test not complete" 0 "test complete" ;
VAL_ 2566835966 ComprehensiveComponentMonSupp 3 "Not available" 2 "Reserved" 1 "test supported" 0 "test not supported" ;
VAL_ 2566835966 FuelSystemMonitoringSupport 1 "test supported" 0 "test not supported" ;
VAL_ 2566764286 SPNSupportTypeSTR3 1 "NotSupportedInScaledTestResults" 0 "SupportedInScaledTestResults" ;
VAL_ 2566764286 SPNSupportTypeSTR2 1 "NotSupportedInScaledTestResults" 0 "SupportedInScaledTestResults" ;
VAL_ 2566764286 SPNSupportTypeEFF3 1 "NotSupportedInExFreezeFrame" 0 "SupportedInExFreezeFrame" ;
VAL_ 2566764286 SPNSupportTypeEFF2 1 "NotSupportedInExFreezeFrame" 0 "SupportedInExFreezeFrame" ;
VAL_ 2566764286 SPNSupportTypeDS3 1 "NotSupportedInDataStream" 0 "SupportedInDataStream" ;
VAL_ 2566764286 SPNSupportTypeDS2 1 "NotSupportedInDataStream" 0 "SupportedInDataStream" ;
VAL_ 2566764286 SPNSupportTypeSTR1 1 "NotSupportedInScaledTestResults" 0 "SupportedInScaledTestResults" ;
VAL_ 2566764286 SPNSupportTypeDS1 1 "NotSupportedInDataStream" 0 "SupportedInDataStream" ;
VAL_ 2566764286 SPNSupportTypeEFF1 1 "NotSupportedInExFreezeFrame" 0 "SupportedInExFreezeFrame" ;
VAL_ 2566764030 FlashRedStopLamp 3 "Unavailable / Do Not Flash" 2 "Reserved" 1 "Fast Flash" 0 "Slow Flash" ;
VAL_ 2566764030 FlashProtectLamp 3 "Unavailable / Do Not Flash" 2 "Reserved" 1 "Fast Flash" 0 "Slow Flash" ;
VAL_ 2566764030 FlashMalfuncIndicatorLamp 3 "Unavailable / Do Not Flash" 2 "Reserved" 1 "Fast Flash" 0 "Slow Flash" ;
VAL_ 2566764030 FlashAmberWarningLamp 3 "Unavailable / Do Not Flash" 2 "Reserved" 1 "Fast Flash" 0 "Slow Flash" ;
VAL_ 2566764030 MalfunctionIndicatorLampStatus 3 "Not available" 2 "Reserved" 1 "Lamp on" 0 "Lamp off" ;
VAL_ 2566764030 RedStopLampState 3 "Not available" 2 "Reserved" 1 "Lamp on" 0 "Lamp off" ;
VAL_ 2566764030 AmberWarningLampStatus 3 "Not available" 2 "Reserved" 1 "Lamp on" 0 "Lamp off" ;
VAL_ 2566764030 ProtectLampStatus 3 "Not available" 2 "Reserved" 1 "Lamp on" 0 "Lamp off" ;
VAL_ 2562981630 FailureModeIdentifier1 31 "Not available" 19 "Received network data in error" 18 "Below normal (moderately severe)" 17 "Below normal (least severe)" 16 "Above normal (moderately severe)" 15 "Above normal (least severe)" 14 "Special intstructions" 13 "Out of calibration" 12 "Bad intelligent device" 11 "Root cause not known" 10 "Abnormal rate of change" 9 "Abnormal update rate" 8 "Abnormal frequency" 7 "Mechanical system not responding" 6 "Current above normal" 5 "Current below normal" 4 "Voltage below normal" 3 "Voltage above normal" 2 "Data erratic" 1 "Below normal (most severe)" 0 "Above normal (most severe)" ;
